VERSION ""

NS_ :

BS_:

BU_: Vector__XXX ECU SenderNode

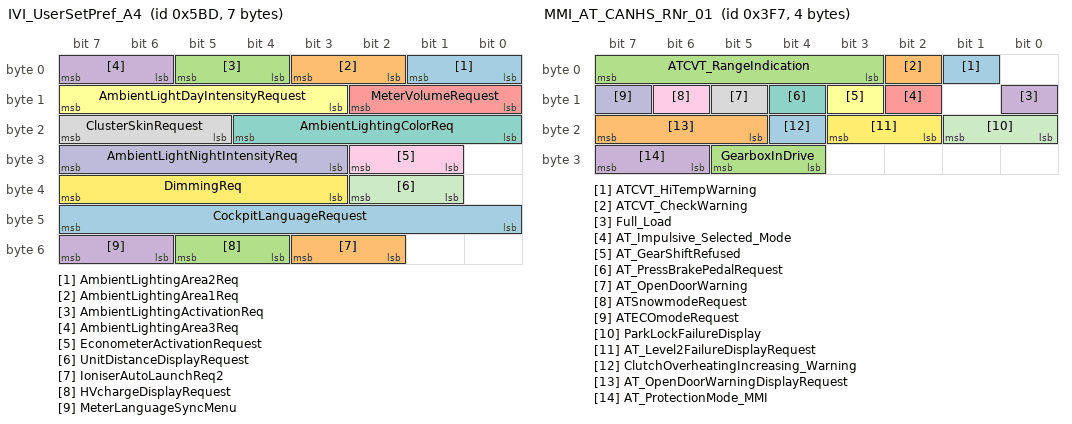
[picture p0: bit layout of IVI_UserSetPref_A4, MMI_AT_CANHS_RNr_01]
BO_ 1469 IVI_UserSetPref_A4: 7 Vector__XXX
 SG_ AmbientLightingArea2Req : 1|2@0+ (1.0,0.0) [0|0] "" Vector__XXX
 SG_ AmbientLightingArea1Req : 3|2@0+ (1.0,0.0) [0|0] "" Vector__XXX
 SG_ AmbientLightingActivationReq : 5|2@0+ (1.0,0.0) [0|0] "" Vector__XXX
 SG_ AmbientLightingArea3Req : 7|2@0+ (1.0,0.0) [0|0] "" Vector__XXX
 SG_ MeterVolumeRequest : 10|3@0+ (1.0,0.0) [0|0] "" Vector__XXX
 SG_ AmbientLightDayIntensityRequest : 15|5@0+ (1.0,0.0) [0|0] "" Vector__XXX
 SG_ AmbientLightingColorReq : 20|5@0+ (1.0,0.0) [0|0] "" Vector__XXX
 SG_ ClusterSkinRequest : 23|3@0+ (1.0,0.0) [0|0] "" Vector__XXX
 SG_ EconometerActivationRequest : 26|2@0+ (1.0,0.0) [0|0] "" Vector__XXX
 SG_ AmbientLightNightIntensityReq : 31|5@0+ (1.0,0.0) [0|0] "" Vector__XXX
 SG_ UnitDistanceDisplayRequest : 34|2@0+ (1.0,0.0) [0|0] "" Vector__XXX
 SG_ DimmingReq : 39|5@0+ (1.0,0.0) [0|0] "" Vector__XXX
 SG_ CockpitLanguageRequest : 47|8@0+ (1.0,0.0) [0|0] "" Vector__XXX
 SG_ IoniserAutoLaunchReq2 : 51|2@0+ (1.0,0.0) [0|0] "" Vector__XXX
 SG_ HVchargeDisplayRequest : 53|2@0+ (1.0,0.0) [0|0] "" Vector__XXX
 SG_ MeterLanguageSyncMenu : 55|2@0+ (1.0,0.0) [0|0] "" Vector__XXX

BO_ 1974 LBC2_to_DTOOL: 8 Vector__XXX
 SG_ LBC2_to_DTOOL : 7|64@0+ (1.0,0.0) [0|0] "" Vector__XXX

BO_ 1199 LBC_CANHS_R_09: 5 Vector__XXX
 SG_ ClosedCircuit_CellMaxVoltage_Threshold : 0|9@0+ (1.0,0.0) [0|0] "" Vector__XXX
 SG_ HVB_TempMinStopCooling_Threshold : 7|7@0+ (1.0,0.0) [0|0] "" Vector__XXX
 SG_ ClosedCircuit_CellMinVoltage_Threshold : 23|9@0+ (1.0,0.0) [0|0] "" Vector__XXX
 SG_ HVB_MaxCapacity : 30|9@0+ (0.1,0.0) [0|0] "kWh" Vector__XXX

BO_ 1979 LBC_to_DTOOL: 8 Vector__XXX
 SG_ LBC_to_DTOOL : 7|64@0+ (1.0,0.0) [0|0] "" Vector__XXX

BO_ 1826 LINSCH_to_DTOOL: 8 Vector__XXX
 SG_ LINSCH_to_DTOOL : 7|64@0+ (1.0,0.0) [0|0] "" Vector__XXX

BO_ 1015 MMI_AT_CANHS_RNr_01: 4 Vector__XXX
 SG_ ATCVT_HiTempWarning : 1|1@0+ (1.0,0.0) [0|0] "" Vector__XXX
 SG_ ATCVT_CheckWarning : 2|1@0+ (1.0,0.0) [0|0] "" Vector__XXX
 SG_ ATCVT_RangeIndication : 7|5@0+ (1.0,0.0) [0|0] "" Vector__XXX
 SG_ Full_Load : 8|1@0+ (1.0,0.0) [0|0] "" Vector__XXX
 SG_ AT_Impulsive_Selected_Mode : 10|1@0+ (1.0,0.0) [0|0] "" Vector__XXX
 SG_ AT_GearShiftRefused : 11|1@0+ (1.0,0.0) [0|0] "" Vector__XXX
 SG_ AT_PressBrakePedalRequest : 12|1@0+ (1.0,0.0) [0|0] "" Vector__XXX
 SG_ AT_OpenDoorWarning : 13|1@0+ (1.0,0.0) [0|0] "" Vector__XXX
 SG_ ATSnowmodeRequest : 14|1@0+ (1.0,0.0) [0|0] "" Vector__XXX
 SG_ ATECOmodeRequest : 15|1@0+ (1.0,0.0) [0|0] "" Vector__XXX
 SG_ ParkLockFailureDisplay : 17|2@0+ (1.0,0.0) [0|0] "" Vector__XXX
 SG_ AT_Level2FailureDisplayRequest : 19|2@0+ (1.0,0.0) [0|0] "" Vector__XXX
 SG_ ClutchOverheatingIncreasing_Warning : 20|1@0+ (1.0,0.0) [0|0] "" Vector__XXX
 SG_ AT_OpenDoorWarningDisplayRequest : 23|3@0+ (1.0,0.0) [0|0] "" Vector__XXX
 SG_ GearboxInDrive : 29|2@0+ (1.0,0.0) [0|0] "" Vector__XXX
 SG_ AT_ProtectionMode_MMI : 31|2@0+ (1.0,0.0) [0|0] "" Vector__XXX

BO_ 1502 MMI_BCM_CANHS_R_01: 8 Vector__XXX
 SG_ HighBeamDisplay : 0|1@0+ (1.0,0.0) [0|0] "" Vector__XXX
 SG_ LowBeamDisplay : 1|1@0+ (1.0,0.0) [0|0] "" Vector__XXX
 SG_ PositionLightsDisplay : 2|1@0+ (1.0,0.0) [0|0] "" Vector__XXX
 SG_ FrontFogLightsDisplay : 3|1@0+ (1.0,0.0) [0|0] "" Vector__XXX
 SG_ RearFogLightStateDisplay : 4|1@0+ (1.0,0.0) [0|0] "" Vector__XXX
 SG_ FlashingIndicatorStatusDisplay : 7|3@0+ (1.0,0.0) [0|0] "" Vector__XXX
 SG_ KeyInfoReemissionRequest : 8|1@0+ (1.0,0.0) [0|0] "" Vector__XXX
 SG_ FrontRightDoorOpenWarning : 10|2@0+ (1.0,0.0) [0|0] "" Vector__XXX
 SG_ FrontLeftDoorOpenWarning : 12|2@0+ (1.0,0.0) [0|0] "" Vector__XXX
 SG_ ALS_Malfunction : 13|1@0+ (1.0,0.0) [0|0] "" Vector__XXX
 SG_ PositionLightsOmissionWarning : 15|2@0+ (1.0,0.0) [0|0] "" Vector__XXX
 SG_ UnlockingSteeringColumnWarning : 16|1@0+ (1.0,0.0) [0|0] "" Vector__XXX
 SG_ SteeringLock_Failure : 18|2@0+ (1.0,0.0) [0|0] "" Vector__XXX
 SG_ BDUSafetyLineFailure : 19|1@0+ (1.0,0.0) [0|0] "" Vector__XXX
 SG_ RearRightDoorOpenWarning : 21|2@0+ (1.0,0.0) [0|0] "" Vector__XXX
 SG_ RearLeftDoorOpenWarning : 23|2@0+ (1.0,0.0) [0|0] "" Vector__XXX
 SG_ StartAutoInformationDisplay : 25|2@0+ (1.0,0.0) [0|0] "" Vector__XXX
 SG_ TripDisplayScrollingRequest : 27|2@0+ (1.0,0.0) [0|0] "" Vector__XXX
 SG_ ChildproofLockMalfunctionDisplay : 29|2@0+ (1.0,0.0) [0|0] "" Vector__XXX
 SG_ BadgeBatteryLow : 30|1@0+ (1.0,0.0) [0|0] "" Vector__XXX
 SG_ AutomaticLockUpActivationState : 31|1@0+ (1.0,0.0) [0|0] "" Vector__XXX
 SG_ DRLstate : 33|2@0+ (1.0,0.0) [0|0] "" Vector__XXX
 SG_ KeylessCardReaderFailureDisplay : 34|1@0+ (1.0,0.0) [0|0] "" Vector__XXX
 SG_ KeylessInfoReemissionRequest : 35|1@0+ (1.0,0.0) [0|0] "" Vector__XXX
 SG_ SmartKeylessInformationDisplay : 39|4@0+ (1.0,0.0) [0|0] "" Vector__XXX
 SG_ BrakeSwitchFaultDisplay : 40|1@0+ (1.0,0.0) [0|0] "" Vector__XXX
 SG_ ClutchSwitchFaultDisplay : 41|1@0+ (1.0,0.0) [0|0] "" Vector__XXX
 SG_ ManualLockDisplayRequest : 42|1@0+ (1.0,0.0) [0|0] "" Vector__XXX
 SG_ SingleDoorOpeningState : 44|2@0+ (1.0,0.0) [0|0] "" Vector__XXX
 SG_ FollowMeHomeDurationDisplay : 47|3@0+ (1.0,0.0) [0|0] "" Vector__XXX
 SG_ KeyInformationDisplay : 50|3@0+ (1.0,0.0) [0|0] "" Vector__XXX
 SG_ AutomaticLockUpInhibitionWarning : 51|1@0+ (1.0,0.0) [0|0] "" Vector__XXX
 SG_ VarPowSteeringFailureDisplay : 52|1@0+ (1.0,0.0) [0|0] "" Vector__XXX
 SG_ FlashingIndicatorFailureDisplay : 53|1@0+ (1.0,0.0) [0|0] "" Vector__XXX
 SG_ StopLampFailureDisplay_BCM : 54|1@0+ (1.0,0.0) [0|0] "" Vector__XXX
 SG_ MexSwitchState : 55|1@0+ (1.0,0.0) [0|0] "" Vector__XXX
 SG_ EcoModeStatusDisplay : 57|2@0+ (1.0,0.0) [0|0] "" Vector__XXX
 SG_ GlasshatchOpenWarning : 59|2@0+ (1.0,0.0) [0|0] "" Vector__XXX
 SG_ BootOpenWarning : 61|2@0+ (1.0,0.0) [0|0] "" Vector__XXX
 SG_ RearWiperStatus : 63|2@0+ (1.0,0.0) [0|0] "" Vector__XXX

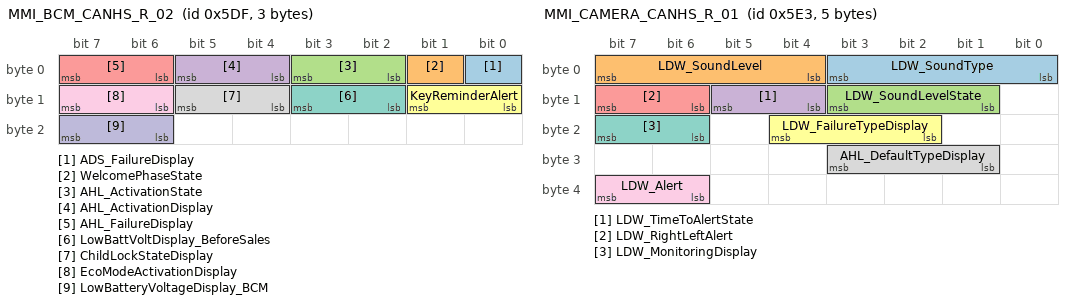
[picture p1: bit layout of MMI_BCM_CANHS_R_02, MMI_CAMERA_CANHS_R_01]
BO_ 1503 MMI_BCM_CANHS_R_02: 3 Vector__XXX
 SG_ ADS_FailureDisplay : 0|1@0+ (1.0,0.0) [0|0] "" Vector__XXX
 SG_ WelcomePhaseState : 1|1@0+ (1.0,0.0) [0|0] "" Vector__XXX
 SG_ AHL_ActivationState : 3|2@0+ (1.0,0.0) [0|0] "" Vector__XXX
 SG_ AHL_ActivationDisplay : 5|2@0+ (1.0,0.0) [0|0] "" Vector__XXX
 SG_ AHL_FailureDisplay : 7|2@0+ (1.0,0.0) [0|0] "" Vector__XXX
 SG_ KeyReminderAlert : 9|2@0+ (1.0,0.0) [0|0] "" Vector__XXX
 SG_ LowBattVoltDisplay_BeforeSales : 11|2@0+ (1.0,0.0) [0|0] "" Vector__XXX
 SG_ ChildLockStateDisplay : 13|2@0+ (1.0,0.0) [0|0] "" Vector__XXX
 SG_ EcoModeActivationDisplay : 15|2@0+ (1.0,0.0) [0|0] "" Vector__XXX
 SG_ LowBatteryVoltageDisplay_BCM : 23|2@0+ (1.0,0.0) [0|0] "" Vector__XXX

BO_ 1638 MMI_BRAKE_CANHS_RNr_01: 4 Vector__XXX
 SG_ EmergencyBrakingFailure : 0|1@0+ (1.0,0.0) [0|0] "" Vector__XXX
 SG_ EBVInDefaultDisplayRequest : 1|1@0+ (1.0,0.0) [0|0] "" Vector__XXX
 SG_ ESPDeactivatedByDriverForDisplay : 2|1@0+ (1.0,0.0) [0|0] "" Vector__XXX
 SG_ ABSInDefaultDisplayRequest : 3|1@0+ (1.0,0.0) [0|0] "" Vector__XXX
 SG_ ASRActivationStateForDisplay : 4|1@0+ (1.0,0.0) [0|0] "" Vector__XXX
 SG_ ESPActivationStateForDisplay : 5|1@0+ (1.0,0.0) [0|0] "" Vector__XXX
 SG_ ESPInDefaultDisplayRequest : 6|1@0+ (1.0,0.0) [0|0] "" Vector__XXX
 SG_ ESPInRegulationDisplayRequest : 7|1@0+ (1.0,0.0) [0|0] "" Vector__XXX
 SG_ ABSorESPToBeCalibrated : 8|1@0+ (1.0,0.0) [0|0] "" Vector__XXX
 SG_ ABSorESPInCalibratingDiag : 9|1@0+ (1.0,0.0) [0|0] "" Vector__XXX
 SG_ FHSA_MalfunctionDisplayRequest : 10|1@0+ (1.0,0.0) [0|0] "" Vector__XXX
 SG_ FHSA_DriverActionRequest : 11|1@0+ (1.0,0.0) [0|0] "" Vector__XXX
 SG_ FHSA_HoldStatusDisplayRequest : 12|1@0+ (1.0,0.0) [0|0] "" Vector__XXX
 SG_ FHSA_DeactivationDisplayRequest : 14|2@0+ (1.0,0.0) [0|0] "" Vector__XXX
 SG_ ABS_ESPLampsAutoCheck : 15|1@0+ (1.0,0.0) [0|0] "" Vector__XXX
 SG_ HSAFailureDisplayRequest : 16|1@0+ (1.0,0.0) [0|0] "" Vector__XXX
 SG_ ACCInactiveRegulationDisplay : 18|2@0+ (1.0,0.0) [0|0] "" Vector__XXX
 SG_ RST_EspAsrSportMode : 21|3@0+ (1.0,0.0) [0|0] "" Vector__XXX
 SG_ VSUStateDisplayRequest : 23|2@0+ (1.0,0.0) [0|0] "" Vector__XXX
 SG_ TPW_AckResetDriver : 25|2@0+ (1.0,0.0) [0|0] "" Vector__XXX
 SG_ TPW_Status : 27|2@0+ (1.0,0.0) [0|0] "" Vector__XXX
 SG_ ExtendedGripModeDisplayRequest : 30|3@0+ (1.0,0.0) [0|0] "" Vector__XXX
 SG_ HSA_HoldStatusDisplayRequest : 31|1@0+ (1.0,0.0) [0|0] "" Vector__XXX

BO_ 1507 MMI_CAMERA_CANHS_R_01: 5 Vector__XXX
 SG_ LDW_SoundType : 3|4@0+ (1.0,0.0) [0|0] "" Vector__XXX
 SG_ LDW_SoundLevel : 7|4@0+ (1.0,0.0) [0|0] "" Vector__XXX
 SG_ LDW_SoundLevelState : 11|3@0+ (1.0,0.0) [0|0] "" Vector__XXX
 SG_ LDW_TimeToAlertState : 13|2@0+ (1.0,0.0) [0|0] "" Vector__XXX
 SG_ LDW_RightLeftAlert : 15|2@0+ (1.0,0.0) [0|0] "" Vector__XXX
 SG_ LDW_FailureTypeDisplay : 20|3@0+ (1.0,0.0) [0|0] "" Vector__XXX
 SG_ LDW_MonitoringDisplay : 23|2@0+ (1.0,0.0) [0|0] "" Vector__XXX
 SG_ AHL_DefaultTypeDisplay : 27|3@0+ (1.0,0.0) [0|0] "" Vector__XXX
 SG_ LDW_Alert : 39|2@0+ (1.0,0.0) [0|0] "" Vector__XXX

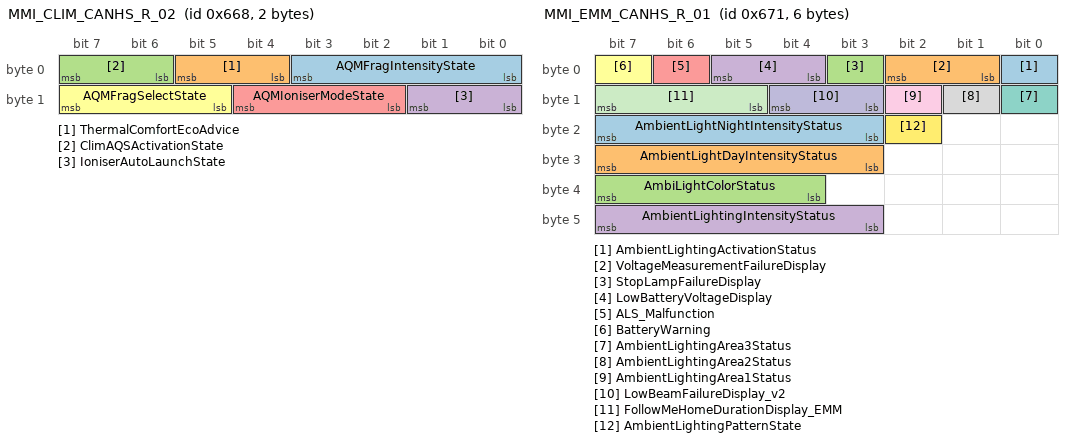
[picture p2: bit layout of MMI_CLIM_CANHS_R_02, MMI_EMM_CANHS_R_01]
BO_ 1640 MMI_CLIM_CANHS_R_02: 2 Vector__XXX
 SG_ AQMFragIntensityState : 3|4@0+ (1.0,0.0) [0|0] "" Vector__XXX
 SG_ ThermalComfortEcoAdvice : 5|2@0+ (1.0,0.0) [0|0] "" Vector__XXX
 SG_ ClimAQSActivationState : 7|2@0+ (1.0,0.0) [0|0] "" Vector__XXX
 SG_ IoniserAutoLaunchState : 9|2@0+ (1.0,0.0) [0|0] "" Vector__XXX
 SG_ AQMIoniserModeState : 12|3@0+ (1.0,0.0) [0|0] "" Vector__XXX
 SG_ AQMFragSelectState : 15|3@0+ (1.0,0.0) [0|0] "" Vector__XXX

BO_ 1689 MMI_CLIM_CANHS_R_03: 8 Vector__XXX
 SG_ ClimModeTypeDisplay : 3|3@0+ (1.0,0.0) [0|0] "" Vector__XXX
 SG_ ClimRearDefrostDisplay : 5|2@0+ (1.0,0.0) [0|0] "" Vector__XXX
 SG_ ClimOFFButtonDisplay : 7|2@0+ (1.0,0.0) [0|0] "" Vector__XXX
 SG_ ClimTempDisplay : 15|8@0+ (1.0,0.0) [0|0] "" Vector__XXX
 SG_ ClimECOModeStatusDisplay : 17|2@0+ (1.0,0.0) [0|0] "" Vector__XXX
 SG_ ClimForcedRecyDisplay : 19|2@0+ (1.0,0.0) [0|0] "" Vector__XXX
 SG_ ClimFlowDistrDisplay : 23|4@0+ (1.0,0.0) [0|0] "" Vector__XXX
 SG_ ClimLastFuncModifiedByCustomer : 27|4@0+ (1.0,0.0) [0|0] "" Vector__XXX
 SG_ ClimBlowerLevelDisplay : 31|4@0+ (1.0,0.0) [0|0] "" Vector__XXX
 SG_ ClimAQSIndicator : 37|6@0+ (2.0,0.0) [0|0] "%" Vector__XXX
 SG_ ClimMMIActivationRequest : 39|2@0+ (1.0,0.0) [0|0] "" Vector__XXX
 SG_ ClimAQMIoniserTimerDisplay : 41|6@0+ (1.0,0.0) [0|0] "" Vector__XXX
 SG_ ClimAQMIoniserMaxTimerDisplay : 47|6@0+ (1.0,0.0) [0|0] "" Vector__XXX
 SG_ ClimACOffDisplay : 49|2@0+ (1.0,0.0) [0|0] "" Vector__XXX
 SG_ ClimAutoDisplay : 51|2@0+ (1.0,0.0) [0|0] "" Vector__XXX
 SG_ ClimEcoLowSocDisplay : 56|1@0+ (1.0,0.0) [0|0] "" Vector__XXX
 SG_ ClimOFFPromptingDisplay : 57|1@0+ (1.0,0.0) [0|0] "" Vector__XXX
 SG_ EnergyFlowForThermalComfortDisplay : 59|2@0+ (1.0,0.0) [0|0] "" Vector__XXX
 SG_ ClimDisplayMenuPC : 61|2@0+ (1.0,0.0) [0|0] "" Vector__XXX
 SG_ ClimClearnessDisplay : 63|2@0+ (1.0,0.0) [0|0] "" Vector__XXX

BO_ 1642 MMI_ECM_CANHS_RNr_01: 8 Vector__XXX
 SG_ CruiseControlStatusDisplay : 2|3@0+ (1.0,0.0) [0|0] "" Vector__XXX
 SG_ MILLamp : 6|4@0+ (1.0,0.0) [0|0] "" Vector__XXX
 SG_ DieselPreHeating : 7|1@0+ (1.0,0.0) [0|0] "" Vector__XXX
 SG_ RequestedSpeedDisplayRequest : 15|8@0+ (1.0,0.0) [0|0] "" Vector__XXX
 SG_ FuelConsumptionType : 16|1@0+ (1.0,0.0) [0|0] "" Vector__XXX
 SG_ ParticulateFilterFailureDisplay : 17|1@0+ (1.0,0.0) [0|0] "" Vector__XXX
 SG_ ParticulateFilterState : 18|1@0+ (1.0,0.0) [0|0] "" Vector__XXX
 SG_ DieselFilterWaterDetection : 19|1@0+ (1.0,0.0) [0|0] "" Vector__XXX
 SG_ WarningWaterTemp : 20|1@0+ (1.0,0.0) [0|0] "" Vector__XXX
 SG_ EngineControlFailureLevel2 : 21|1@0+ (1.0,0.0) [0|0] "" Vector__XXX
 SG_ EngineControlFailureLevel1 : 22|1@0+ (1.0,0.0) [0|0] "" Vector__XXX
 SG_ OverspeedIndicationDisplayReq : 23|1@0+ (1.0,0.0) [0|0] "" Vector__XXX
 SG_ FuelConsumption : 31|8@0+ (80.0,0.0) [0|0] "mm3" Vector__XXX
 SG_ NominalFuelConsumption : 39|8@0+ (80.0,0.0) [0|0] "mm3" Vector__XXX
 SG_ DMSActivationRefusedDisplay : 40|2@0+ (1.0,0.0) [0|0] "" Vector__XXX
 SG_ DMSFailureDisplay : 41|1@0+ (1.0,0.0) [0|0] "" Vector__XXX
 SG_ DMSActivationStateDisplay : 42|1@0+ (1.0,0.0) [0|0] "" Vector__XXX
 SG_ RST_GearShift : 43|1@0+ (1.0,0.0) [0|0] "" Vector__XXX
 SG_ LPGFlowSwitchedOFFWarning : 44|1@0+ (1.0,0.0) [0|0] "" Vector__XXX
 SG_ CCSpeedReachedDisplayReq : 45|1@0+ (1.0,0.0) [0|0] "" Vector__XXX
 SG_ FreeShift : 47|2@0+ (1.0,0.0) [0|0] "" Vector__XXX
 SG_ EnginePowerDisplay : 52|5@0+ (1.0,0.0) [0|0] "" Vector__XXX
 SG_ AdditionalTankFuelLowLevel : 53|1@0+ (1.0,0.0) [0|0] "" Vector__XXX
 SG_ OverSpeedAlert_SL : 54|1@0+ (1.0,0.0) [0|0] "" Vector__XXX
 SG_ RST_VehicleMode_MMI : 59|3@0+ (1.0,0.0) [0|0] "" Vector__XXX

BO_ 1608 MMI_ECM_CANHS_R_02: 8 Vector__XXX
 SG_ SCR_DistanceAutonomyDisplay : 1|10@0+ (1.0,0.0) [0|0] "" Vector__XXX
 SG_ SCR_UreaLevelDisplay : 5|4@0+ (1.0,0.0) [0|0] "" Vector__XXX
 SG_ SCR_WarningDISDisplay : 7|2@0+ (1.0,0.0) [0|0] "" Vector__XXX
 SG_ SailingIdleDisplay : 16|2@0+ (1.0,0.0) [0|0] "" Vector__XXX
 SG_ SailingActivationIdleStatus : 17|1@0+ (1.0,0.0) [0|0] "" Vector__XXX
 SG_ SCR_WarningPostDISDisplay : 19|2@0+ (1.0,0.0) [0|0] "" Vector__XXX
 SG_ SCR_QualityWarningBeforeDISDisplay : 21|2@0+ (1.0,0.0) [0|0] "" Vector__XXX
 SG_ SCR_WarningBeforeDISDisplay : 23|2@0+ (1.0,0.0) [0|0] "" Vector__XXX
 SG_ AccelerationIndicator : 30|7@0+ (1.0,0.0) [0|0] "%" Vector__XXX
 SG_ FluentDrivingIndicator : 39|7@0+ (1.0,0.0) [0|0] "%" Vector__XXX
 SG_ GSI_Respect : 46|7@0+ (1.0,0.0) [0|0] "%" Vector__XXX
 SG_ LPGModeDisplayRequest : 48|1@0+ (1.0,0.0) [0|0] "" Vector__XXX
 SG_ AdvisorEconometer : 55|7@0+ (1.0,0.0) [0|0] "%" Vector__XXX
 SG_ SCR_DISWarningDisplayReactivation : 56|1@0+ (1.0,0.0) [0|0] "" Vector__XXX
 SG_ FlexFuelPreHeatingDisplay : 58|2@0+ (1.0,0.0) [0|0] "" Vector__XXX
 SG_ SCR_DISFinalWarningDisplay : 60|2@0+ (1.0,0.0) [0|0] "" Vector__XXX
 SG_ CapFuelTankStatusDisplay : 62|2@0+ (1.0,0.0) [0|0] "" Vector__XXX
 SG_ LPG_NGSystemMalfunction : 63|1@0+ (1.0,0.0) [0|0] "" Vector__XXX

BO_ 1050 MMI_ECM_CANHS_R_03: 8 Vector__XXX
 SG_ StartAutoInformationDisplay_ECM : 1|2@0+ (1.0,0.0) [0|0] "" Vector__XXX
 SG_ StopStartSwitchMMI : 2|1@0+ (1.0,0.0) [0|0] "" Vector__XXX
 SG_ StopStartExitReminderDisplay_ECM : 4|2@0+ (1.0,0.0) [0|0] "" Vector__XXX
 SG_ StopAutoUnavailableDisplayRequest_ECM : 5|1@0+ (1.0,0.0) [0|0] "" Vector__XXX
 SG_ StopStartStateDisplayRequest_ECM : 7|2@0+ (1.0,0.0) [0|0] "" Vector__XXX
 SG_ BattWarnReq_Level_Lo_ECM : 8|1@0+ (1.0,0.0) [0|0] "" Vector__XXX
 SG_ BattWarnReq_Level_Hi_ECM : 9|1@0+ (1.0,0.0) [0|0] "" Vector__XXX
 SG_ ECM_OilPressureSwitchFaultDisplay : 10|1@0+ (1.0,0.0) [0|0] "" Vector__XXX
 SG_ DeclutchPromptingDisplayRequest_ECM : 12|2@0+ (1.0,0.0) [0|0] "" Vector__XXX
 SG_ StopStartManualCrankingDisplay : 15|3@0+ (1.0,0.0) [0|0] "" Vector__XXX
 SG_ ManualPartFilterRegeStatus : 19|2@0+ (1.0,0.0) [0|0] "" Vector__XXX
 SG_ GasLowLevelAlertDisplayRequest : 20|1@0+ (1.0,0.0) [0|0] "" Vector__XXX
 SG_ GasInstantCarburationMod : 21|1@0+ (1.0,0.0) [0|0] "" Vector__XXX
 SG_ StopAutoStateDisplayRequest_ECM : 22|1@0+ (1.0,0.0) [0|0] "" Vector__XXX
 SG_ OilPressureWarning_ECM : 23|1@0+ (1.0,0.0) [0|0] "" Vector__XXX
 SG_ SCR_UreaLevelDisplay_V2 : 31|8@0+ (1.0,0.0) [0|0] "" Vector__XXX
 SG_ CNGFuelConsumption : 39|8@0+ (1e-05,0.0) [0|0] "kg" Vector__XXX
 SG_ LPGLevelForDisplay : 47|8@0+ (0.25,0.0) [0|0] "L" Vector__XXX
 SG_ LPGFuelConsumption : 55|8@0+ (2e-05,0.0) [0|0] "L" Vector__XXX
 SG_ CNGLevelForDisplay : 63|8@0+ (0.2,0.0) [0|0] "kg" Vector__XXX

BO_ 1649 MMI_EMM_CANHS_R_01: 6 Vector__XXX
 SG_ AmbientLightingActivationStatus : 0|1@0+ (1.0,0.0) [0|0] "" Vector__XXX
 SG_ VoltageMeasurementFailureDisplay : 2|2@0+ (1.0,0.0) [0|0] "" Vector__XXX
 SG_ StopLampFailureDisplay : 3|1@0+ (1.0,0.0) [0|0] "" Vector__XXX
 SG_ LowBatteryVoltageDisplay : 5|2@0+ (1.0,0.0) [0|0] "" Vector__XXX
 SG_ ALS_Malfunction : 6|1@0+ (1.0,0.0) [0|0] "" Vector__XXX
 SG_ BatteryWarning : 7|1@0+ (1.0,0.0) [0|0] "" Vector__XXX
 SG_ AmbientLightingArea3Status : 8|1@0+ (1.0,0.0) [0|0] "" Vector__XXX
 SG_ AmbientLightingArea2Status : 9|1@0+ (1.0,0.0) [0|0] "" Vector__XXX
 SG_ AmbientLightingArea1Status : 10|1@0+ (1.0,0.0) [0|0] "" Vector__XXX
 SG_ LowBeamFailureDisplay_v2 : 12|2@0+ (1.0,0.0) [0|0] "" Vector__XXX
 SG_ FollowMeHomeDurationDisplay_EMM : 15|3@0+ (1.0,0.0) [0|0] "" Vector__XXX
 SG_ AmbientLightingPatternState : 18|1@0+ (1.0,0.0) [0|0] "" Vector__XXX
 SG_ AmbientLightNightIntensityStatus : 23|5@0+ (1.0,0.0) [0|0] "" Vector__XXX
 SG_ AmbientLightDayIntensityStatus : 31|5@0+ (1.0,0.0) [0|0] "" Vector__XXX
 SG_ AmbiLightColorStatus : 39|4@0+ (1.0,0.0) [0|0] "" Vector__XXX
 SG_ AmbientLightingIntensityStatus : 47|5@0+ (1.0,0.0) [0|0] "" Vector__XXX

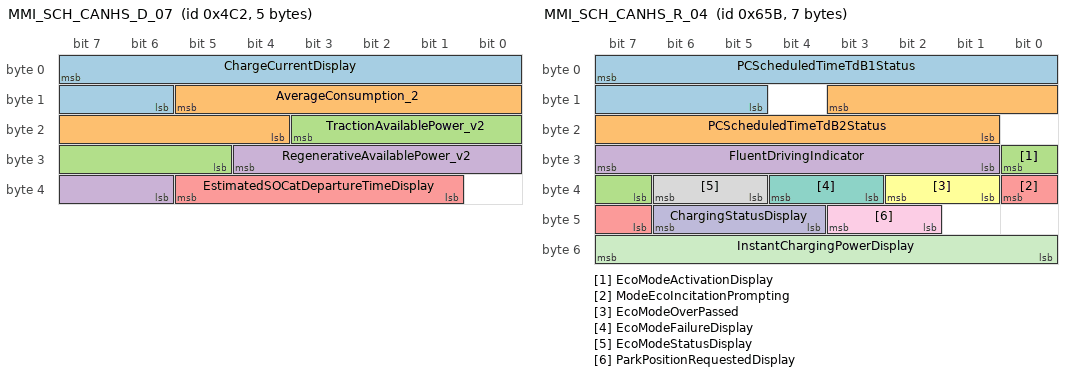
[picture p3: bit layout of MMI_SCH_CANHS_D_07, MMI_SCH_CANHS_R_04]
BO_ 1218 MMI_SCH_CANHS_D_07: 5 Vector__XXX
 SG_ ChargeCurrentDisplay : 7|10@0+ (0.1,0.0) [0|0] "A" Vector__XXX
 SG_ AverageConsumption_2 : 13|10@0+ (0.1,0.0) [0|0] "kWh/100km" Vector__XXX
 SG_ TractionAvailablePower_v2 : 19|7@0+ (1.0,0.0) [0|0] "KW" Vector__XXX
 SG_ RegenerativeAvailablePower_v2 : 28|7@0+ (1.0,0.0) [0|0] "KW" Vector__XXX
 SG_ EstimatedSOCatDepartureTimeDisplay : 37|5@0+ (5.0,0.0) [0|0] "%" Vector__XXX

BO_ 1618 MMI_SCH_CANHS_R_01: 8 Vector__XXX
 SG_ ElectricalConsumption : 7|8@0+ (1.0,0.0) [0|0] "" Vector__XXX
 SG_ InstantConsumption : 11|12@0+ (1.0,0.0) [0|0] "" Vector__XXX
 SG_ Battery14VLowDisplayRequest : 13|2@0+ (1.0,0.0) [0|0] "" Vector__XXX
 SG_ ElectricalEngineState : 14|1@0+ (1.0,0.0) [0|0] "" Vector__XXX
 SG_ CrankingRequest : 15|1@0+ (1.0,0.0) [0|0] "" Vector__XXX
 SG_ ETAlertIsolationLevel1 : 25|2@0+ (1.0,0.0) [0|0] "" Vector__XXX
 SG_ ETAlertETSDefault : 27|2@0+ (1.0,0.0) [0|0] "" Vector__XXX
 SG_ ETAlertRepairETSDefault : 29|2@0+ (1.0,0.0) [0|0] "" Vector__XXX
 SG_ Battery14VWarningDisplayRequest : 31|2@0+ (1.0,0.0) [0|0] "" Vector__XXX
 SG_ TotalConsumption : 37|14@0+ (1.0,0.0) [0|0] "" Vector__XXX
 SG_ ETAlertIsolationLevel2 : 39|2@0+ (1.0,0.0) [0|0] "" Vector__XXX
 SG_ ETAlertDCDCDefault : 49|2@0+ (1.0,0.0) [0|0] "" Vector__XXX
 SG_ ETAlertPerfLimitation2 : 51|2@0+ (1.0,0.0) [0|0] "" Vector__XXX
 SG_ ETAlertPerfLimitation1 : 53|2@0+ (1.0,0.0) [0|0] "" Vector__XXX
 SG_ ETAlertMotorDefault : 55|2@0+ (1.0,0.0) [0|0] "" Vector__XXX
 SG_ SCH_StopLampRequest : 57|2@0+ (1.0,0.0) [0|0] "" Vector__XXX
 SG_ SCH_WarningRequest : 59|2@0+ (1.0,0.0) [0|0] "" Vector__XXX
 SG_ ETAlertPerfLimitation3 : 61|2@0+ (1.0,0.0) [0|0] "" Vector__XXX
 SG_ EMOverSpeed : 63|2@0+ (1.0,0.0) [0|0] "" Vector__XXX

BO_ 1620 MMI_SCH_CANHS_R_02: 8 Vector__XXX
 SG_ UnballastStateDisplay : 0|1@0+ (1.0,0.0) [0|0] "" Vector__XXX
 SG_ SnowModeRequest : 1|1@0+ (1.0,0.0) [0|0] "" Vector__XXX
 SG_ PedalPressRequested : 2|1@0+ (1.0,0.0) [0|0] "" Vector__XXX
 SG_ HVBatteryUnballastAlert : 3|1@0+ (1.0,0.0) [0|0] "" Vector__XXX
 SG_ DriverWalkAwayEngineON : 4|1@0+ (1.0,0.0) [0|0] "" Vector__XXX
 SG_ ChargingPlugConnected : 5|1@0+ (1.0,0.0) [0|0] "" Vector__XXX
 SG_ BoilerStateDisplay : 6|1@0+ (1.0,0.0) [0|0] "" Vector__XXX
 SG_ BoilerLevelStateDisplay : 7|1@0+ (1.0,0.0) [0|0] "" Vector__XXX
 SG_ HVBatteryFailureDisplay : 15|2@0+ (1.0,0.0) [0|0] "" Vector__XXX
 SG_ DriverWalkAwayBoilerON : 17|1@0+ (1.0,0.0) [0|0] "" Vector__XXX
 SG_ SelectedGear : 19|2@0+ (1.0,0.0) [0|0] "" Vector__XXX
 SG_ PreHeatingState : 21|2@0+ (1.0,0.0) [0|0] "" Vector__XXX
 SG_ ElectricalChargingType : 23|2@0+ (1.0,0.0) [0|0] "" Vector__XXX
 SG_ HVBatteryEnergyLevel : 30|7@0+ (1.0,0.0) [0|0] "%" Vector__XXX
 SG_ DriverWalkAwayOnParking_Request : 31|1@0+ (1.0,0.0) [0|0] "" Vector__XXX
 SG_ SlowChargeRemainingTime : 39|10@0+ (1.0,0.0) [0|0] "min" Vector__XXX
 SG_ VehicleAutonomy : 45|10@0+ (1.0,0.0) [0|0] "km" Vector__XXX
 SG_ AverageConsumption : 51|10@0+ (0.1,0.0) [0|0] "kWh/100km" Vector__XXX
 SG_ HVBatteryLow : 56|1@0+ (1.0,0.0) [0|0] "" Vector__XXX

BO_ 1616 MMI_SCH_CANHS_R_03: 8 Vector__XXX
 SG_ EnergyFlowForTractionDisplay : 1|2@0+ (1.0,0.0) [0|0] "" Vector__XXX
 SG_ EnergyFlowForThermalComfortDisplay : 3|2@0+ (1.0,0.0) [0|0] "" Vector__XXX
 SG_ EnergyFlowForHardBrakingDisplay : 5|2@0+ (1.0,0.0) [0|0] "" Vector__XXX
 SG_ EnergyFlowForEnergyRecoveringDisplay : 7|2@0+ (1.0,0.0) [0|0] "" Vector__XXX
 SG_ QuickDropUnlockedDisplay : 9|2@0+ (1.0,0.0) [0|0] "" Vector__XXX
 SG_ QuickDropLockFailureDisplay : 11|2@0+ (1.0,0.0) [0|0] "" Vector__XXX
 SG_ QuickDropIterationExceededDisplay : 13|2@0+ (1.0,0.0) [0|0] "" Vector__XXX
 SG_ ShortRangeDisplay : 15|2@0+ (1.0,0.0) [0|0] "" Vector__XXX
 SG_ AdvisorEconometer : 23|7@0+ (1.0,0.0) [0|0] "%" Vector__XXX
 SG_ CrankingPluggedDisplay : 25|2@0+ (1.0,0.0) [0|0] "" Vector__XXX
 SG_ EBAAlertLevel2 : 27|2@0+ (1.0,0.0) [0|0] "" Vector__XXX
 SG_ EBAAlertLevel1 : 29|2@0+ (1.0,0.0) [0|0] "" Vector__XXX
 SG_ JBDefaultLevel2 : 35|2@0+ (1.0,0.0) [0|0] "" Vector__XXX
 SG_ JBDefaultLevel1 : 37|2@0+ (1.0,0.0) [0|0] "" Vector__XXX
 SG_ GearboxChangeOnCrankingRequest : 39|2@0+ (1.0,0.0) [0|0] "" Vector__XXX
 SG_ ChargeRemainingTimeDisplay : 41|9@0+ (5.0,0.0) [0|0] "min" Vector__XXX
 SG_ HVConnectionStatusDisplay : 42|1@0+ (1.0,0.0) [0|0] "" Vector__XXX
 SG_ PreHeatingStateDisplay : 45|3@0+ (1.0,0.0) [0|0] "" Vector__XXX
 SG_ ClimProgrammedPCDisplay : 47|2@0+ (1.0,0.0) [0|0] "" Vector__XXX
 SG_ RadarRecuperationStatusDisplay : 57|2@0+ (1.0,0.0) [0|0] "" Vector__XXX
 SG_ EngineDryingDisplayRequest : 63|2@0+ (1.0,0.0) [0|0] "" Vector__XXX

BO_ 1627 MMI_SCH_CANHS_R_04: 7 Vector__XXX
 SG_ PCScheduledTimeTdB1Status : 7|11@0+ (1.0,0.0) [0|0] "min" Vector__XXX
 SG_ PCScheduledTimeTdB2Status : 11|11@0+ (1.0,0.0) [0|0] "min" Vector__XXX
 SG_ EcoModeActivationDisplay : 24|2@0+ (1.0,0.0) [0|0] "" Vector__XXX
 SG_ FluentDrivingIndicator : 31|7@0+ (1.0,0.0) [0|0] "%" Vector__XXX
 SG_ ModeEcoIncitationPrompting : 32|2@0+ (1.0,0.0) [0|0] "" Vector__XXX
 SG_ EcoModeOverPassed : 34|2@0+ (1.0,0.0) [0|0] "" Vector__XXX
 SG_ EcoModeFailureDisplay : 36|2@0+ (1.0,0.0) [0|0] "" Vector__XXX
 SG_ EcoModeStatusDisplay : 38|2@0+ (1.0,0.0) [0|0] "" Vector__XXX
 SG_ ParkPositionRequestedDisplay : 43|2@0+ (1.0,0.0) [0|0] "" Vector__XXX
 SG_ ChargingStatusDisplay : 46|3@0+ (1.0,0.0) [0|0] "" Vector__XXX
 SG_ InstantChargingPowerDisplay : 55|8@0+ (0.3,0.0) [0|0] "kW" Vector__XXX

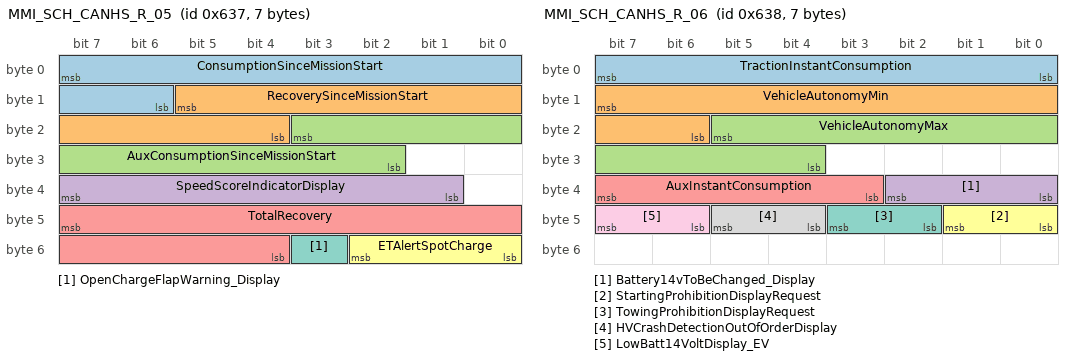
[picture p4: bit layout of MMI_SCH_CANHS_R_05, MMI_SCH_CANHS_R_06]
BO_ 1591 MMI_SCH_CANHS_R_05: 7 Vector__XXX
 SG_ ConsumptionSinceMissionStart : 7|10@0+ (0.1,0.0) [0|0] "kWh" Vector__XXX
 SG_ RecoverySinceMissionStart : 13|10@0+ (0.1,0.0) [0|0] "kWh" Vector__XXX
 SG_ AuxConsumptionSinceMissionStart : 19|10@0+ (0.1,0.0) [0|0] "kWh" Vector__XXX
 SG_ SpeedScoreIndicatorDisplay : 39|7@0+ (1.0,0.0) [0|0] "%" Vector__XXX
 SG_ TotalRecovery : 47|12@0+ (1.0,0.0) [0|0] "kWh" Vector__XXX
 SG_ ETAlertSpotCharge : 50|3@0+ (1.0,0.0) [0|0] "" Vector__XXX
 SG_ OpenChargeFlapWarning_Display : 51|1@0+ (1.0,0.0) [0|0] "" Vector__XXX

BO_ 1592 MMI_SCH_CANHS_R_06: 7 Vector__XXX
 SG_ TractionInstantConsumption : 7|8@0- (1.0,-80.0) [0|0] "kW" Vector__XXX
 SG_ VehicleAutonomyMin : 15|10@0+ (1.0,0.0) [0|0] "km" Vector__XXX
 SG_ VehicleAutonomyMax : 21|10@0+ (1.0,0.0) [0|0] "km" Vector__XXX
 SG_ Battery14vToBeChanged_Display : 34|3@0+ (1.0,0.0) [0|0] "" Vector__XXX
 SG_ AuxInstantConsumption : 39|5@0+ (1.0,0.0) [0|0] "kW" Vector__XXX
 SG_ StartingProhibitionDisplayRequest : 41|2@0+ (1.0,0.0) [0|0] "" Vector__XXX
 SG_ TowingProhibitionDisplayRequest : 43|2@0+ (1.0,0.0) [0|0] "" Vector__XXX
 SG_ HVCrashDetectionOutOfOrderDisplay : 45|2@0+ (1.0,0.0) [0|0] "" Vector__XXX
 SG_ LowBatt14VoltDisplay_EV : 47|2@0+ (1.0,0.0) [0|0] "" Vector__XXX

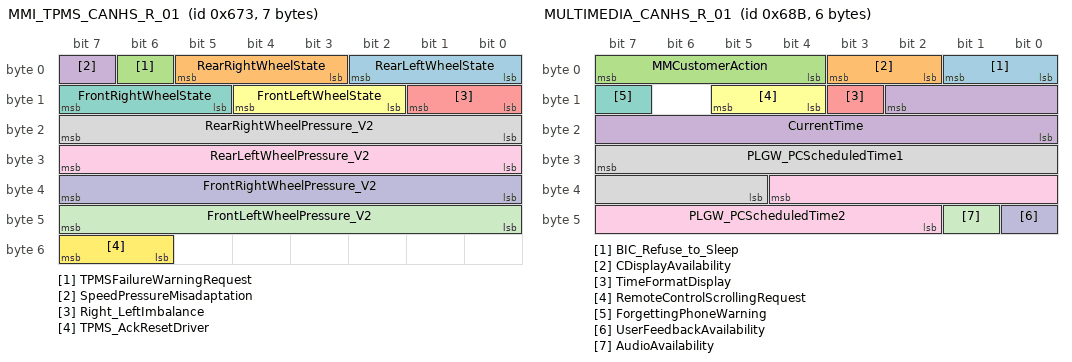
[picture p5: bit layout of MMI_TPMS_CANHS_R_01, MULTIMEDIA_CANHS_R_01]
BO_ 1651 MMI_TPMS_CANHS_R_01: 7 Vector__XXX
 SG_ RearLeftWheelState : 2|3@0+ (1.0,0.0) [0|0] "" Vector__XXX
 SG_ RearRightWheelState : 5|3@0+ (1.0,0.0) [0|0] "" Vector__XXX
 SG_ TPMSFailureWarningRequest : 6|1@0+ (1.0,0.0) [0|0] "" Vector__XXX
 SG_ SpeedPressureMisadaptation : 7|1@0+ (1.0,0.0) [0|0] "" Vector__XXX
 SG_ Right_LeftImbalance : 9|2@0+ (1.0,0.0) [0|0] "" Vector__XXX
 SG_ FrontLeftWheelState : 12|3@0+ (1.0,0.0) [0|0] "" Vector__XXX
 SG_ FrontRightWheelState : 15|3@0+ (1.0,0.0) [0|0] "" Vector__XXX
 SG_ RearRightWheelPressure_V2 : 23|8@0+ (30.0,0.0) [0|0] "mbar" Vector__XXX
 SG_ RearLeftWheelPressure_V2 : 31|8@0+ (30.0,0.0) [0|0] "mbar" Vector__XXX
 SG_ FrontRightWheelPressure_V2 : 39|8@0+ (30.0,0.0) [0|0] "mbar" Vector__XXX
 SG_ FrontLeftWheelPressure_V2 : 47|8@0+ (30.0,0.0) [0|0] "mbar" Vector__XXX
 SG_ TPMS_AckResetDriver : 55|2@0+ (1.0,0.0) [0|0] "" Vector__XXX

BO_ 1675 MULTIMEDIA_CANHS_R_01: 6 Vector__XXX
 SG_ BIC_Refuse_to_Sleep : 1|2@0+ (1.0,0.0) [0|0] "" Vector__XXX
 SG_ CDisplayAvailability : 3|2@0+ (1.0,0.0) [0|0] "" Vector__XXX
 SG_ MMCustomerAction : 7|4@0+ (1.0,0.0) [0|0] "" Vector__XXX
 SG_ CurrentTime : 10|11@0+ (1.0,0.0) [0|0] "min" Vector__XXX
 SG_ TimeFormatDisplay : 11|1@0+ (1.0,0.0) [0|0] "" Vector__XXX
 SG_ RemoteControlScrollingRequest : 13|2@0+ (1.0,0.0) [0|0] "" Vector__XXX
 SG_ ForgettingPhoneWarning : 15|1@0+ (1.0,0.0) [0|0] "" Vector__XXX
 SG_ PLGW_PCScheduledTime1 : 31|11@0+ (1.0,0.0) [0|0] "" Vector__XXX
 SG_ PLGW_PCScheduledTime2 : 36|11@0+ (1.0,0.0) [0|0] "" Vector__XXX
 SG_ UserFeedbackAvailability : 40|1@0+ (1.0,0.0) [0|0] "" Vector__XXX
 SG_ AudioAvailability : 41|1@0+ (1.0,0.0) [0|0] "" Vector__XXX

BO_ 1895 NAV_to_DTOOL: 8 Vector__XXX
 SG_ NAV_to_DTOOL : 7|64@0+ (1.0,0.0) [0|0] "" Vector__XXX

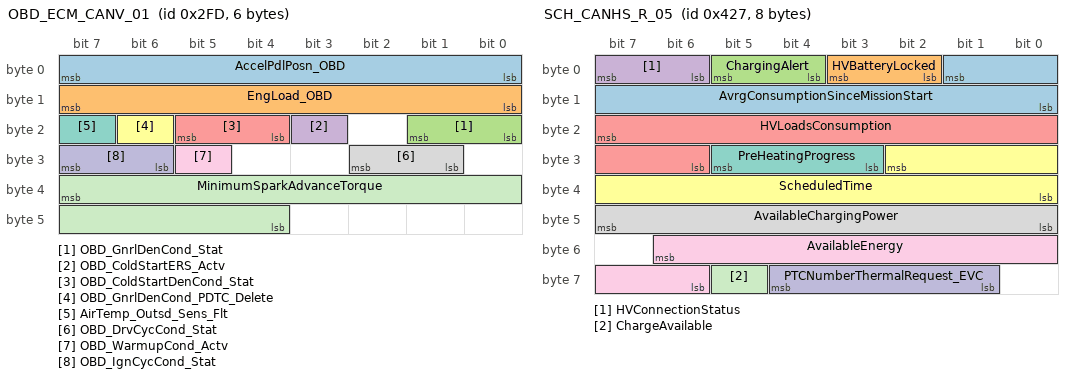
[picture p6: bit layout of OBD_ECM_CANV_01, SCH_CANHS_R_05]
BO_ 765 OBD_ECM_CANV_01: 6 Vector__XXX
 SG_ AccelPdlPosn_OBD : 7|8@0+ (0.392157,0.0) [0|0] "%" Vector__XXX
 SG_ EngLoad_OBD : 15|8@0+ (0.392157,0.0) [0|0] "%" Vector__XXX
 SG_ OBD_GnrlDenCond_Stat : 17|2@0+ (1.0,0.0) [0|0] "" Vector__XXX
 SG_ OBD_ColdStartERS_Actv : 19|1@0+ (1.0,0.0) [0|0] "" Vector__XXX
 SG_ OBD_ColdStartDenCond_Stat : 21|2@0+ (1.0,0.0) [0|0] "" Vector__XXX
 SG_ OBD_GnrlDenCond_PDTC_Delete : 22|1@0+ (1.0,0.0) [0|0] "" Vector__XXX
 SG_ AirTemp_Outsd_Sens_Flt : 23|1@0+ (1.0,0.0) [0|0] "" Vector__XXX
 SG_ OBD_DrvCycCond_Stat : 26|2@0+ (1.0,0.0) [0|0] "" Vector__XXX
 SG_ OBD_WarmupCond_Actv : 29|1@0+ (1.0,0.0) [0|0] "" Vector__XXX
 SG_ OBD_IgnCycCond_Stat : 31|2@0+ (1.0,0.0) [0|0] "" Vector__XXX
 SG_ MinimumSparkAdvanceTorque : 39|12@0- (0.5,-400.0) [0|0] "Nm" Vector__XXX

BO_ 1095 OFF_BOARD_TCU_01: 3 Vector__XXX
 SG_ TCU_PCScheduledTime1 : 5|11@0+ (1.0,0.0) [0|0] "min" Vector__XXX
 SG_ TCU_ClimPCCustomerActiv : 7|2@0+ (1.0,0.0) [0|0] "" Vector__XXX
 SG_ TCU_PCScheduledTime2 : 10|11@0+ (1.0,0.0) [0|0] "min" Vector__XXX

BO_ 1918 PEB_to_DTOOL: 8 Vector__XXX
 SG_ PEB_to_DTOOL : 7|64@0+ (1.0,0.0) [0|0] "" Vector__XXX

BO_ 1992 PLGW_to_DTOOL: 8 Vector__XXX
 SG_ PLGW_to_DTOOL : 7|64@0+ (1.0,0.0) [0|0] "" Vector__XXX

BO_ 1899 ROOF_to_DTOOL: 8 Vector__XXX
 SG_ Roof_to_DTOOL : 7|64@0+ (1.0,0.0) [0|0] "" Vector__XXX

BO_ 1842 Radio_to_DTOOL: 8 Vector__XXX
 SG_ Radio_to_DTOOL : 7|64@0+ (1.0,0.0) [0|0] "" Vector__XXX

BO_ 1485 RemoteFunctionService_BCM_Frame: 8 Vector__XXX
 SG_ RemoteFunctionService_BCM : 7|64@0+ (1.0,0.0) [0|0] "" Vector__XXX

BO_ 1509 RemoteFunctionService_TCU_Frame: 8 Vector__XXX
 SG_ RemoteFunctionService_TCU : 7|64@0+ (1.0,0.0) [0|0] "" Vector__XXX

BO_ 1849 SACHA_to_DTOOL: 8 Vector__XXX
 SG_ SACHA_to_DTOOL : 7|64@0+ (1.0,0.0) [0|0] "" Vector__XXX

BO_ 509 SCH_CANHS_R_01: 8 Vector__XXX
 SG_ DCDCLoad : 7|8@0+ (0.390625,0.0) [0|0] "%" Vector__XXX
 SG_ ElectricalLoadSheddingRequest : 9|2@0+ (1.0,0.0) [0|0] "" Vector__XXX
 SG_ ClimFanReductionRequest : 10|1@0+ (1.0,0.0) [0|0] "" Vector__XXX
 SG_ PreHeatSelectedDisplayRequest : 11|1@0+ (1.0,0.0) [0|0] "" Vector__XXX
 SG_ SCH_TrunkOpeningRequest : 13|2@0+ (1.0,0.0) [0|0] "" Vector__XXX
 SG_ SCH_Refuse_to_Sleep : 15|2@0+ (1.0,0.0) [0|0] "" Vector__XXX
 SG_ LeftTimeBeforeVehicleWakeUp : 18|11@0+ (1.0,0.0) [0|0] "" Vector__XXX
 SG_ StartPreHeatingCounter : 20|2@0+ (1.0,0.0) [0|0] "" Vector__XXX
 SG_ StopPreHeatingCounter : 22|2@0+ (1.0,0.0) [0|0] "" Vector__XXX
 SG_ BoilerOnDoorOpen : 23|1@0+ (1.0,0.0) [0|0] "" Vector__XXX
 SG_ LeftTimeToScheduledTime : 38|7@0+ (1.0,0.0) [0|0] "min" Vector__XXX
 SG_ PreHeatingActivation : 39|1@0+ (1.0,0.0) [0|0] "" Vector__XXX
 SG_ ClimAvailablePower : 47|8@0+ (25.0,0.0) [0|0] "W" Vector__XXX
 SG_ Econometer : 55|8@0- (1.0,-80.0) [0|0] "kW" Vector__XXX
 SG_ AT_GearShiftRefused : 56|1@0+ (1.0,0.0) [0|0] "" Vector__XXX
 SG_ SCH_BlowerRequest : 57|1@0+ (1.0,0.0) [0|0] "" Vector__XXX
 SG_ BMS_TiAlertDisplay : 63|1@0+ (1.0,0.0) [0|0] "" Vector__XXX

BO_ 1063 SCH_CANHS_R_05: 8 Vector__XXX
 SG_ AvrgConsumptionSinceMissionStart : 1|10@0+ (1.0,0.0) [0|0] "" Vector__XXX
 SG_ HVBatteryLocked : 3|2@0+ (1.0,0.0) [0|0] "" Vector__XXX
 SG_ ChargingAlert : 5|2@0+ (1.0,0.0) [0|0] "" Vector__XXX
 SG_ HVConnectionStatus : 7|2@0+ (1.0,0.0) [0|0] "" Vector__XXX
 SG_ HVLoadsConsumption : 23|10@0+ (10.0,0.0) [0|0] "W" Vector__XXX
 SG_ ScheduledTime : 26|11@0+ (1.0,0.0) [0|0] "" Vector__XXX
 SG_ PreHeatingProgress : 29|3@0+ (1.0,0.0) [0|0] "" Vector__XXX
 SG_ AvailableChargingPower : 47|8@0+ (0.3,0.0) [0|0] "kW" Vector__XXX
 SG_ AvailableEnergy : 54|9@0+ (0.1,0.0) [0|0] "kWh" Vector__XXX
 SG_ PTCNumberThermalRequest_EVC : 60|4@0+ (1.0,0.0) [0|0] "" Vector__XXX
 SG_ ChargeAvailable : 61|1@0+ (1.0,0.0) [0|0] "" Vector__XXX

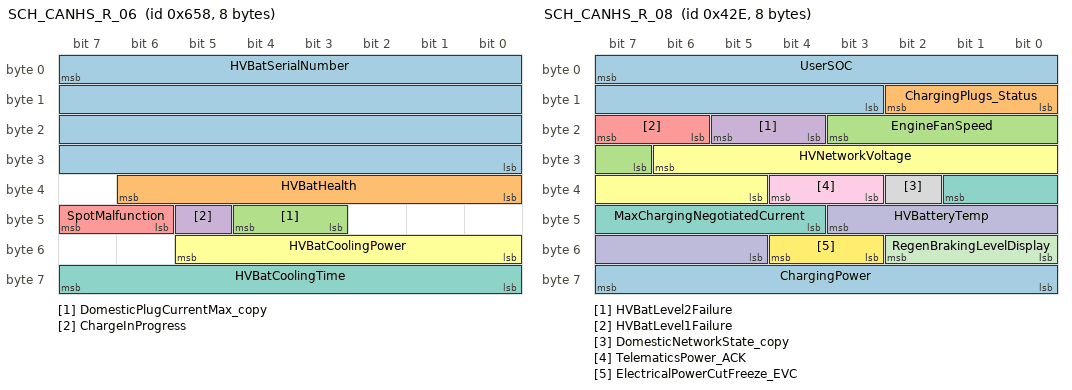
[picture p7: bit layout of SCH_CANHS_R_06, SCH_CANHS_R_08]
BO_ 1624 SCH_CANHS_R_06: 8 Vector__XXX
 SG_ HVBatSerialNumber : 7|32@0+ (1.0,0.0) [0|0] "" Vector__XXX
 SG_ HVBatHealth : 38|7@0+ (1.0,0.0) [0|0] "%" Vector__XXX
 SG_ DomesticPlugCurrentMax_copy : 44|2@0+ (1.0,0.0) [0|0] "" Vector__XXX
 SG_ ChargeInProgress : 45|1@0+ (1.0,0.0) [0|0] "" Vector__XXX
 SG_ SpotMalfunction : 47|2@0+ (1.0,0.0) [0|0] "" Vector__XXX
 SG_ HVBatCoolingPower : 53|6@0+ (1.0,0.0) [0|0] "" Vector__XXX
 SG_ HVBatCoolingTime : 63|8@0+ (1.0,0.0) [0|0] "" Vector__XXX

BO_ 1070 SCH_CANHS_R_08: 8 Vector__XXX
 SG_ UserSOC : 7|13@0+ (0.02,0.0) [0|0] "%" Vector__XXX
 SG_ ChargingPlugs_Status : 10|3@0+ (1.0,0.0) [0|0] "" Vector__XXX
 SG_ EngineFanSpeed : 19|5@0+ (5.0,0.0) [0|0] "%" Vector__XXX
 SG_ HVBatLevel2Failure : 21|2@0+ (1.0,0.0) [0|0] "" Vector__XXX
 SG_ HVBatLevel1Failure : 23|2@0+ (1.0,0.0) [0|0] "" Vector__XXX
 SG_ HVNetworkVoltage : 30|10@0+ (0.5,0.0) [0|0] "V" Vector__XXX
 SG_ MaxChargingNegotiatedCurrent : 33|6@0+ (1.0,0.0) [0|0] "A" Vector__XXX
 SG_ DomesticNetworkState_copy : 34|1@0+ (1.0,0.0) [0|0] "" Vector__XXX
 SG_ TelematicsPower_ACK : 36|2@0+ (1.0,0.0) [0|0] "" Vector__XXX
 SG_ HVBatteryTemp : 43|7@0- (1.0,-40.0) [0|0] "°C" Vector__XXX
 SG_ RegenBrakingLevelDisplay : 50|3@0+ (1.0,0.0) [0|0] "" Vector__XXX
 SG_ ElectricalPowerCutFreeze_EVC : 52|2@0+ (1.0,0.0) [0|0] "" Vector__XXX
 SG_ ChargingPower : 63|8@0+ (1.0,0.0) [0|0] "" Vector__XXX

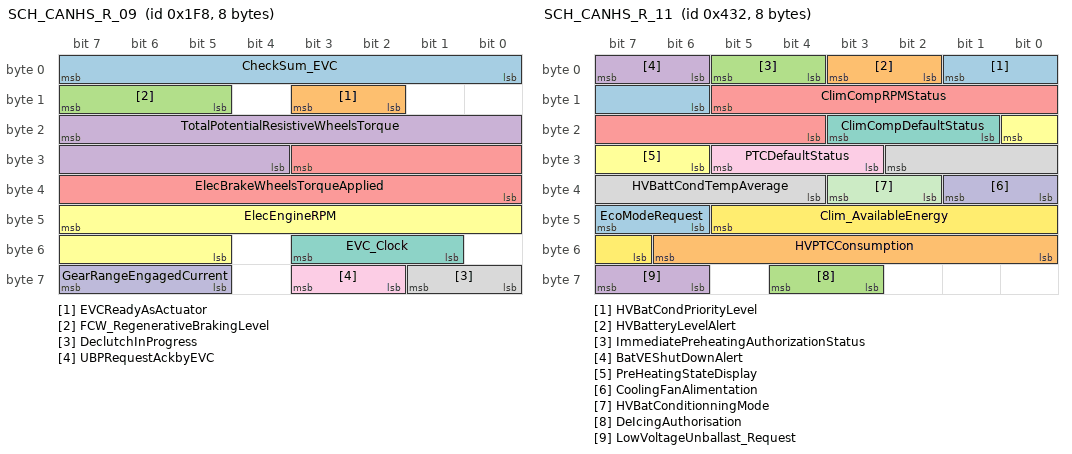
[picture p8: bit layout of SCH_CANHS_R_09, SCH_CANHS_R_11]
BO_ 504 SCH_CANHS_R_09: 8 Vector__XXX
 SG_ CheckSum_EVC : 7|8@0+ (1.0,0.0) [0|0] "" Vector__XXX
 SG_ EVCReadyAsActuator : 11|2@0+ (1.0,0.0) [0|0] "" Vector__XXX
 SG_ FCW_RegenerativeBrakingLevel : 15|3@0+ (1.0,0.0) [0|0] "" Vector__XXX
 SG_ TotalPotentialResistiveWheelsTorque : 23|12@0+ (1.0,0.0) [0|0] "" Vector__XXX
 SG_ ElecBrakeWheelsTorqueApplied : 27|12@0- (1.0,-4094.0) [0|0] "Nm" Vector__XXX
 SG_ ElecEngineRPM : 47|11@0+ (10.0,0.0) [0|0] "Rpm" Vector__XXX
 SG_ EVC_Clock : 51|3@0+ (1.0,0.0) [0|0] "" Vector__XXX
 SG_ DeclutchInProgress : 57|2@0+ (1.0,0.0) [0|0] "" Vector__XXX
 SG_ UBPRequestAckbyEVC : 59|2@0+ (1.0,0.0) [0|0] "" Vector__XXX
 SG_ GearRangeEngagedCurrent : 63|3@0+ (1.0,0.0) [0|0] "" Vector__XXX

BO_ 2047 SCH_CANHS_R_10: 5 Vector__XXX
 SG_ DistanceTotalizer_copy : 7|24@0+ (1.0,0.0) [0|0] "" Vector__XXX
 SG_ VehicleAutonomyZEVdisplay : 31|10@0+ (1.0,0.0) [0|0] "" Vector__XXX

BO_ 1074 SCH_CANHS_R_11: 8 Vector__XXX
 SG_ HVBatCondPriorityLevel : 1|4@0+ (1.0,0.0) [0|0] "" Vector__XXX
 SG_ HVBatteryLevelAlert : 3|2@0+ (1.0,0.0) [0|0] "" Vector__XXX
 SG_ ImmediatePreheatingAuthorizationStatus : 5|2@0+ (1.0,0.0) [0|0] "" Vector__XXX
 SG_ BatVEShutDownAlert : 7|2@0+ (1.0,0.0) [0|0] "" Vector__XXX
 SG_ ClimCompRPMStatus : 13|10@0+ (10.0,0.0) [0|0] "rpm" Vector__XXX
 SG_ PreHeatingStateDisplay : 16|3@0+ (1.0,0.0) [0|0] "" Vector__XXX
 SG_ ClimCompDefaultStatus : 19|3@0+ (1.0,0.0) [0|0] "" Vector__XXX
 SG_ HVBattCondTempAverage : 26|7@0+ (1.0,0.0) [0|0] "" Vector__XXX
 SG_ PTCDefaultStatus : 29|3@0+ (1.0,0.0) [0|0] "" Vector__XXX
 SG_ CoolingFanAlimentation : 33|2@0+ (1.0,0.0) [0|0] "" Vector__XXX
 SG_ HVBatConditionningMode : 35|2@0+ (1.0,0.0) [0|0] "" Vector__XXX
 SG_ Clim_AvailableEnergy : 45|7@0+ (100.0,0.0) [0|0] "Wh" Vector__XXX
 SG_ EcoModeRequest : 47|2@0+ (1.0,0.0) [0|0] "" Vector__XXX
 SG_ HVPTCConsumption : 54|7@0+ (50.0,0.0) [0|0] "W" Vector__XXX
 SG_ DeIcingAuthorisation : 60|2@0+ (1.0,0.0) [0|0] "" Vector__XXX
 SG_ LowVoltageUnballast_Request : 63|2@0+ (1.0,0.0) [0|0] "" Vector__XXX

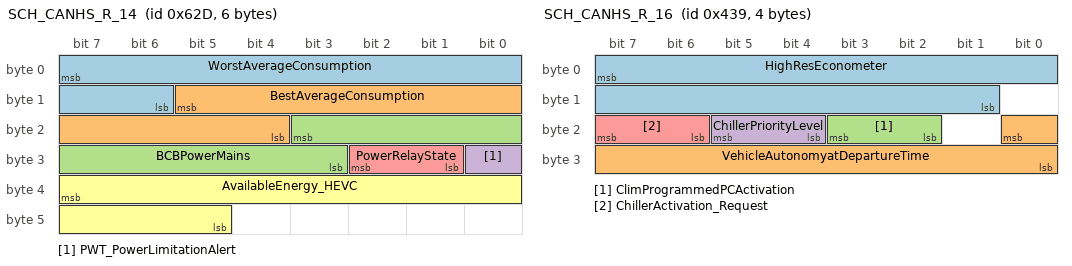
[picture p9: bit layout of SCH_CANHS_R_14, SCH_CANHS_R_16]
BO_ 1581 SCH_CANHS_R_14: 6 Vector__XXX
 SG_ WorstAverageConsumption : 7|10@0+ (0.1,0.0) [0|0] "kWh/100km" Vector__XXX
 SG_ BestAverageConsumption : 13|10@0+ (0.1,0.0) [0|0] "kWh/100km" Vector__XXX
 SG_ BCBPowerMains : 19|9@0+ (100.0,0.0) [0|0] "W" Vector__XXX
 SG_ PWT_PowerLimitationAlert : 24|1@0+ (1.0,0.0) [0|0] "" Vector__XXX
 SG_ PowerRelayState : 26|2@0+ (1.0,0.0) [0|0] "" Vector__XXX
 SG_ AvailableEnergy_HEVC : 39|11@0+ (0.05,0.0) [0|0] "KWh" Vector__XXX

BO_ 1081 SCH_CANHS_R_16: 4 Vector__XXX
 SG_ HighResEconometer : 7|15@0- (0.01,-80.0) [0|0] "KW" Vector__XXX
 SG_ VehicleAutonomyatDepartureTime : 16|9@0+ (5.0,0.0) [0|0] "km" Vector__XXX
 SG_ ClimProgrammedPCActivation : 19|2@0+ (1.0,0.0) [0|0] "" Vector__XXX
 SG_ ChillerPriorityLevel : 21|2@0+ (1.0,0.0) [0|0] "" Vector__XXX
 SG_ ChillerActivation_Request : 23|2@0+ (1.0,0.0) [0|0] "" Vector__XXX

BO_ 2028 SCH_to_DTOOL: 8 Vector__XXX
 SG_ DTOOL_to_SCH : 7|64@0+ (1.0,0.0) [0|0] "" Vector__XXX

BO_ 1981 SHIFTER_to_DTOOL: 8 Vector__XXX
 SG_ SHIFTER_to_DTOOL : 7|64@0+ (1.0,0.0) [0|0] "" Vector__XXX

BO_ 198 SWA_CANHS_RNr_01: 8 Vector__XXX
 SG_ SteeringWheelAngle : 7|16@0- (0.1,-3276.7) [0|0] "°" Vector__XXX
 SG_ SteeringWheelRotationSpeed : 23|16@0- (0.1,-3276.7) [0|0] "°/s" Vector__XXX
 SG_ SteeringWheelAngle_Offset : 39|16@0- (0.1,-3276.7) [0|0] "°" Vector__XXX
 SG_ SwaClock : 52|4@0+ (1.0,0.0) [0|0] "" Vector__XXX
 SG_ SwaSensorInternalStatus : 55|3@0+ (1.0,0.0) [0|0] "" Vector__XXX
 SG_ SwaChecksum : 63|8@0+ (1.0,0.0) [0|0] "" Vector__XXX

BO_ 2033 Scrap_AuthorizationRequestFrame: 8 Vector__XXX
 SG_ Scrap_AuthorizationRequest : 7|64@0+ (1.0,0.0) [0|0] "" Vector__XXX

BO_ 2041 Scrap_AuthorizationStatusFrame: 8 Vector__XXX
 SG_ Scrap_AuthorizationStatus : 7|64@0+ (1.0,0.0) [0|0] "" Vector__XXX

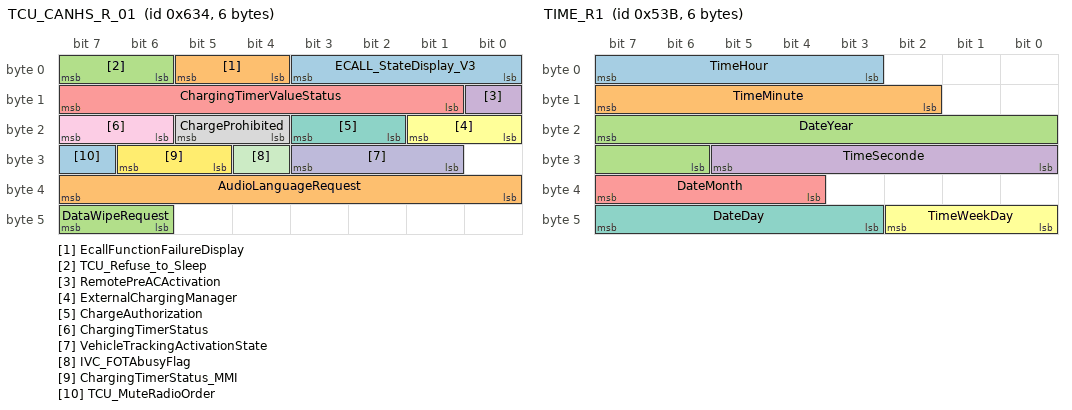
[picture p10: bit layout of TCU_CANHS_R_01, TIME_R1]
BO_ 1588 TCU_CANHS_R_01: 6 Vector__XXX
 SG_ ECALL_StateDisplay_V3 : 3|4@0+ (1.0,0.0) [0|0] "" Vector__XXX
 SG_ EcallFunctionFailureDisplay : 5|2@0+ (1.0,0.0) [0|0] "" Vector__XXX
 SG_ TCU_Refuse_to_Sleep : 7|2@0+ (1.0,0.0) [0|0] "" Vector__XXX
 SG_ RemotePreACActivation : 8|1@0+ (1.0,0.0) [0|0] "" Vector__XXX
 SG_ ChargingTimerValueStatus : 15|7@0+ (1.0,0.0) [0|0] "" Vector__XXX
 SG_ ExternalChargingManager : 17|2@0+ (1.0,0.0) [0|0] "" Vector__XXX
 SG_ ChargeAuthorization : 19|2@0+ (1.0,0.0) [0|0] "" Vector__XXX
 SG_ ChargeProhibited : 21|2@0+ (1.0,0.0) [0|0] "" Vector__XXX
 SG_ ChargingTimerStatus : 23|2@0+ (1.0,0.0) [0|0] "" Vector__XXX
 SG_ VehicleTrackingActivationState : 27|3@0+ (1.0,0.0) [0|0] "" Vector__XXX
 SG_ IVC_FOTAbusyFlag : 28|1@0+ (1.0,0.0) [0|0] "" Vector__XXX
 SG_ ChargingTimerStatus_MMI : 30|2@0+ (1.0,0.0) [0|0] "" Vector__XXX
 SG_ TCU_MuteRadioOrder : 31|1@0+ (1.0,0.0) [0|0] "" Vector__XXX
 SG_ AudioLanguageRequest : 39|8@0+ (1.0,0.0) [0|0] "" Vector__XXX
 SG_ DataWipeRequest : 47|2@0+ (1.0,0.0) [0|0] "" Vector__XXX

BO_ 1372 TCU_WakeUpFrame: 2 Vector__XXX
 SG_ TCU_WakeUp_Signal : 7|16@0+ (1.0,0.0) [0|0] "" Vector__XXX

BO_ 2010 TCU_to_DTOOL: 8 Vector__XXX
 SG_ TCU_to_DTOOL : 7|64@0+ (1.0,0.0) [0|0] "" Vector__XXX

BO_ 1339 TIME_R1: 6 Vector__XXX
 SG_ TimeHour : 7|5@0+ (1.0,0.0) [0|0] "Hour" Vector__XXX
 SG_ TimeMinute : 15|6@0+ (1.0,0.0) [0|0] "Minute" Vector__XXX
 SG_ DateYear : 23|10@0+ (1.0,0.0) [0|0] "" Vector__XXX
 SG_ TimeSeconde : 29|6@0+ (1.0,0.0) [0|0] "" Vector__XXX
 SG_ DateMonth : 39|4@0+ (1.0,0.0) [0|0] "" Vector__XXX
 SG_ TimeWeekDay : 42|3@0+ (1.0,0.0) [0|0] "" Vector__XXX
 SG_ DateDay : 47|5@0+ (1.0,0.0) [0|0] "" Vector__XXX

BO_ 525 TORQUE_AT_CANHS_D_01: 8 Vector__XXX
 SG_ CrankingAuthorisation_AT_Copy : 3|2@0+ (1.0,0.0) [0|0] "" Vector__XXX
 SG_ TransmRangeEngaged_Current_Copy : 7|4@0+ (1.0,0.0) [0|0] "" Vector__XXX
 SG_ AT_TorqueLosses_Copy : 15|8@0+ (0.5,0.0) [0|0] "Nm" Vector__XXX
 SG_ Clock_TORQUE_AT_D_01 : 51|4@0+ (1.0,0.0) [0|0] "" Vector__XXX
 SG_ CRC_TORQUE_AT_D_01 : 63|8@0+ (1.0,0.0) [0|0] "" Vector__XXX

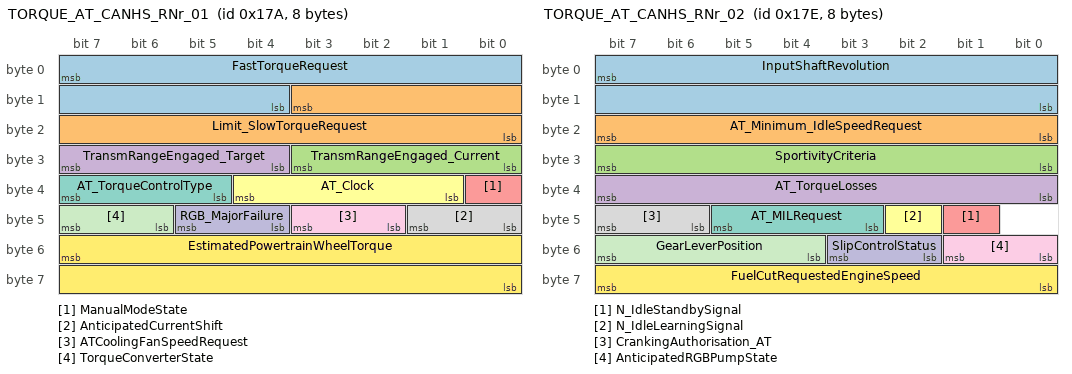
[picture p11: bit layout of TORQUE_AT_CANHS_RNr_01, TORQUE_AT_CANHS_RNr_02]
BO_ 378 TORQUE_AT_CANHS_RNr_01: 8 Vector__XXX
 SG_ FastTorqueRequest : 7|12@0- (0.5,-400.0) [0|0] "Nm" Vector__XXX
 SG_ Limit_SlowTorqueRequest : 11|12@0- (0.5,-400.0) [0|0] "Nm" Vector__XXX
 SG_ TransmRangeEngaged_Current : 27|4@0+ (1.0,0.0) [0|0] "" Vector__XXX
 SG_ TransmRangeEngaged_Target : 31|4@0+ (1.0,0.0) [0|0] "" Vector__XXX
 SG_ ManualModeState : 32|1@0+ (1.0,0.0) [0|0] "" Vector__XXX
 SG_ AT_Clock : 36|4@0+ (1.0,0.0) [0|0] "" Vector__XXX
 SG_ AT_TorqueControlType : 39|3@0+ (1.0,0.0) [0|0] "" Vector__XXX
 SG_ AnticipatedCurrentShift : 41|2@0+ (1.0,0.0) [0|0] "" Vector__XXX
 SG_ ATCoolingFanSpeedRequest : 43|2@0+ (1.0,0.0) [0|0] "" Vector__XXX
 SG_ RGB_MajorFailure : 45|2@0+ (1.0,0.0) [0|0] "" Vector__XXX
 SG_ TorqueConverterState : 47|2@0+ (1.0,0.0) [0|0] "" Vector__XXX
 SG_ EstimatedPowertrainWheelTorque : 55|16@0- (0.5,-6400.0) [0|0] "Nm" Vector__XXX

BO_ 382 TORQUE_AT_CANHS_RNr_02: 8 Vector__XXX
 SG_ InputShaftRevolution : 7|16@0+ (1.0,0.0) [0|0] "rpm" Vector__XXX
 SG_ AT_Minimum_IdleSpeedRequest : 23|8@0+ (8.0,0.0) [0|0] "rpm" Vector__XXX
 SG_ SportivityCriteria : 31|8@0+ (1.0,0.0) [0|0] "" Vector__XXX
 SG_ AT_TorqueLosses : 39|8@0+ (0.5,0.0) [0|0] "Nm" Vector__XXX
 SG_ N_IdleStandbySignal : 41|1@0+ (1.0,0.0) [0|0] "" Vector__XXX
 SG_ N_IdleLearningSignal : 42|1@0+ (1.0,0.0) [0|0] "" Vector__XXX
 SG_ AT_MILRequest : 45|3@0+ (1.0,0.0) [0|0] "" Vector__XXX
 SG_ CrankingAuthorisation_AT : 47|2@0+ (1.0,0.0) [0|0] "" Vector__XXX
 SG_ AnticipatedRGBPumpState : 49|2@0+ (1.0,0.0) [0|0] "" Vector__XXX
 SG_ SlipControlStatus : 51|2@0+ (1.0,0.0) [0|0] "" Vector__XXX
 SG_ GearLeverPosition : 55|4@0+ (1.0,0.0) [0|0] "" Vector__XXX
 SG_ FuelCutRequestedEngineSpeed : 63|8@0+ (1.0,0.0) [0|0] "" Vector__XXX

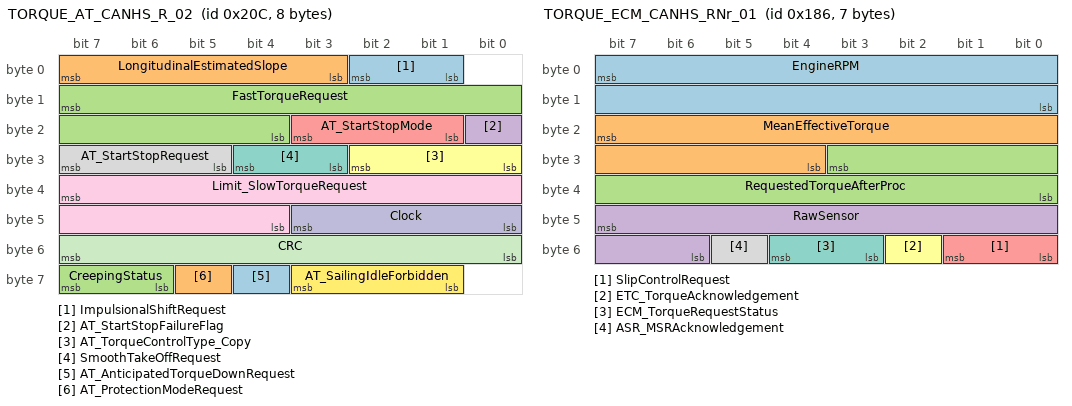
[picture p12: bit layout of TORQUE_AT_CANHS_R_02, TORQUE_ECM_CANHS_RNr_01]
BO_ 524 TORQUE_AT_CANHS_R_02: 8 Vector__XXX
 SG_ ImpulsionalShiftRequest : 2|2@0+ (1.0,0.0) [0|0] "" Vector__XXX
 SG_ LongitudinalEstimatedSlope : 7|5@0+ (1.0,0.0) [0|0] "" Vector__XXX
 SG_ FastTorqueRequest : 15|12@0- (0.5,-400.0) [0|0] "Nm" Vector__XXX
 SG_ AT_StartStopFailureFlag : 16|1@0+ (1.0,0.0) [0|0] "" Vector__XXX
 SG_ AT_StartStopMode : 19|3@0+ (1.0,0.0) [0|0] "" Vector__XXX
 SG_ AT_TorqueControlType_Copy : 26|3@0+ (1.0,0.0) [0|0] "" Vector__XXX
 SG_ SmoothTakeOffRequest : 28|2@0+ (1.0,0.0) [0|0] "" Vector__XXX
 SG_ AT_StartStopRequest : 31|3@0+ (1.0,0.0) [0|0] "" Vector__XXX
 SG_ Limit_SlowTorqueRequest : 39|12@0- (0.5,-400.0) [0|0] "Nm" Vector__XXX
 SG_ Clock : 43|4@0+ (1.0,0.0) [0|0] "" Vector__XXX
 SG_ CRC : 55|8@0+ (1.0,0.0) [0|0] "" Vector__XXX
 SG_ AT_SailingIdleForbidden : 59|3@0+ (1.0,0.0) [0|0] "" Vector__XXX
 SG_ AT_AnticipatedTorqueDownRequest : 60|1@0+ (1.0,0.0) [0|0] "" Vector__XXX
 SG_ AT_ProtectionModeRequest : 61|1@0+ (1.0,0.0) [0|0] "" Vector__XXX
 SG_ CreepingStatus : 63|2@0+ (1.0,0.0) [0|0] "" Vector__XXX

BO_ 390 TORQUE_ECM_CANHS_RNr_01: 7 Vector__XXX
 SG_ EngineRPM : 7|16@0+ (0.125,0.0) [0|0] "rpm" Vector__XXX
 SG_ MeanEffectiveTorque : 23|12@0- (0.5,-400.0) [0|0] "Nm" Vector__XXX
 SG_ RequestedTorqueAfterProc : 27|12@0- (0.5,-400.0) [0|0] "Nm" Vector__XXX
 SG_ RawSensor : 47|10@0+ (0.125,0.0) [0|0] "%" Vector__XXX
 SG_ SlipControlRequest : 49|2@0+ (1.0,0.0) [0|0] "" Vector__XXX
 SG_ ETC_TorqueAcknowledgement : 50|1@0+ (1.0,0.0) [0|0] "" Vector__XXX
 SG_ ECM_TorqueRequestStatus : 52|2@0+ (1.0,0.0) [0|0] "" Vector__XXX
 SG_ ASR_MSRAcknowledgement : 53|1@0+ (1.0,0.0) [0|0] "" Vector__XXX

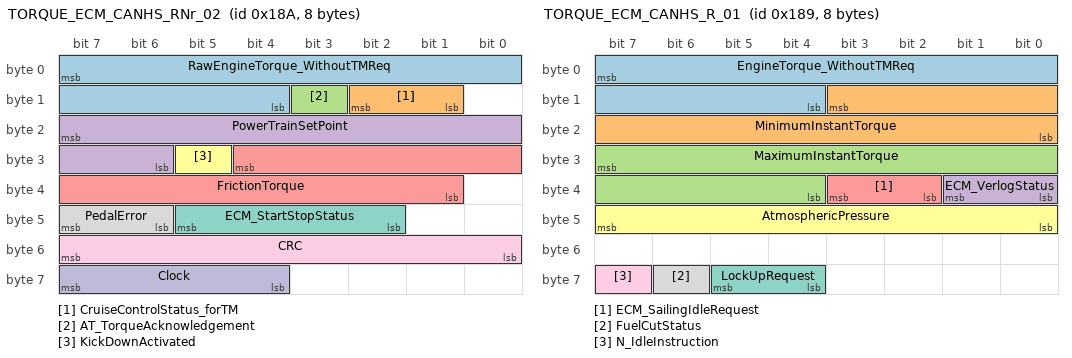
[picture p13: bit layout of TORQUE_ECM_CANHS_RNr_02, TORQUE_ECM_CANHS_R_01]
BO_ 394 TORQUE_ECM_CANHS_RNr_02: 8 Vector__XXX
 SG_ RawEngineTorque_WithoutTMReq : 7|12@0- (0.5,-400.0) [0|0] "Nm" Vector__XXX
 SG_ CruiseControlStatus_forTM : 10|2@0+ (1.0,0.0) [0|0] "" Vector__XXX
 SG_ AT_TorqueAcknowledgement : 11|1@0+ (1.0,0.0) [0|0] "" Vector__XXX
 SG_ PowerTrainSetPoint : 23|10@0+ (0.125,0.0) [0|0] "%" Vector__XXX
 SG_ FrictionTorque : 28|12@0- (0.5,-400.0) [0|0] "Nm" Vector__XXX
 SG_ KickDownActivated : 29|1@0+ (1.0,0.0) [0|0] "" Vector__XXX
 SG_ ECM_StartStopStatus : 45|4@0+ (1.0,0.0) [0|0] "" Vector__XXX
 SG_ PedalError : 47|2@0+ (1.0,0.0) [0|0] "" Vector__XXX
 SG_ CRC : 55|8@0+ (1.0,0.0) [0|0] "" Vector__XXX
 SG_ Clock : 63|4@0+ (1.0,0.0) [0|0] "" Vector__XXX

BO_ 393 TORQUE_ECM_CANHS_R_01: 8 Vector__XXX
 SG_ EngineTorque_WithoutTMReq : 7|12@0- (0.5,-400.0) [0|0] "Nm" Vector__XXX
 SG_ MinimumInstantTorque : 11|12@0- (0.5,-400.0) [0|0] "Nm" Vector__XXX
 SG_ MaximumInstantTorque : 31|12@0- (0.5,-400.0) [0|0] "Nm" Vector__XXX
 SG_ ECM_VerlogStatus : 33|2@0+ (1.0,0.0) [0|0] "" Vector__XXX
 SG_ ECM_SailingIdleRequest : 35|2@0+ (1.0,0.0) [0|0] "" Vector__XXX
 SG_ AtmosphericPressure : 47|8@0+ (2.0,600.0) [0|0] "hPa" Vector__XXX
 SG_ LockUpRequest : 61|2@0+ (1.0,0.0) [0|0] "" Vector__XXX
 SG_ FuelCutStatus : 62|1@0+ (1.0,0.0) [0|0] "" Vector__XXX
 SG_ N_IdleInstruction : 63|1@0+ (1.0,0.0) [0|0] "" Vector__XXX

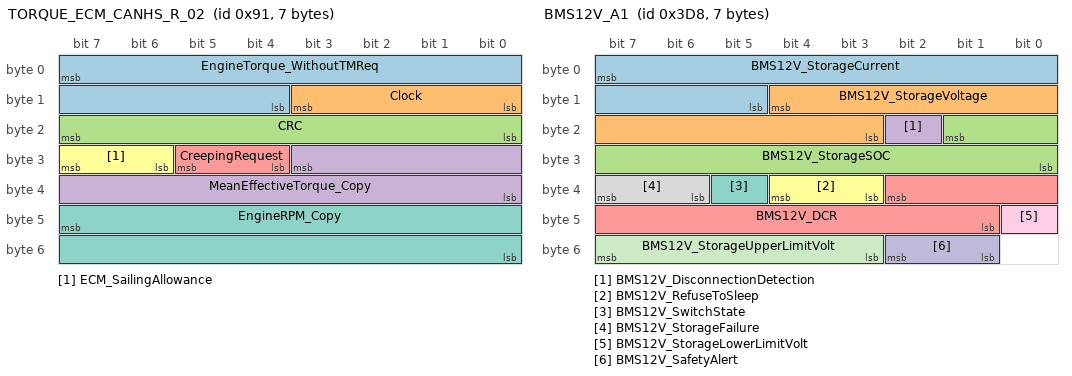
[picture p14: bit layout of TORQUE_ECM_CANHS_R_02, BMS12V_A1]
BO_ 145 TORQUE_ECM_CANHS_R_02: 7 Vector__XXX
 SG_ EngineTorque_WithoutTMReq : 7|12@0- (0.5,-400.0) [0|0] "Nm" Vector__XXX
 SG_ Clock : 11|4@0+ (1.0,0.0) [0|0] "" Vector__XXX
 SG_ CRC : 23|8@0+ (1.0,0.0) [0|0] "" Vector__XXX
 SG_ MeanEffectiveTorque_Copy : 27|12@0- (0.5,-400.0) [0|0] "Nm" Vector__XXX
 SG_ CreepingRequest : 29|2@0+ (1.0,0.0) [0|0] "" Vector__XXX
 SG_ ECM_SailingAllowance : 31|2@0+ (1.0,0.0) [0|0] "" Vector__XXX
 SG_ EngineRPM_Copy : 47|16@0+ (0.125,0.0) [0|0] "Tr/min" Vector__XXX

BO_ 1397 TRACKER_BCM_CANHS_R_01: 2 Vector__XXX
 SG_ TrackerBCM2 : 5|10@0+ (1.0,0.0) [0|0] "" Vector__XXX
 SG_ TrackerBCM1 : 7|2@0+ (1.0,0.0) [0|0] "" Vector__XXX
 SG_ TrackerBCM3 : 11|2@0+ (1.0,0.0) [0|0] "" Vector__XXX

BO_ 1398 TRACKER_TCU_CANHS_R_01: 2 Vector__XXX
 SG_ TrackerTCU2 : 5|10@0+ (1.0,0.0) [0|0] "" Vector__XXX
 SG_ TrackerTCU1 : 7|2@0+ (1.0,0.0) [0|0] "" Vector__XXX
 SG_ TrackerTCU3 : 11|2@0+ (1.0,0.0) [0|0] "" Vector__XXX

BO_ 1901 USM_to_DTOOL: 8 Vector__XXX
 SG_ USM_to_DTOOL : 7|64@0+ (1.0,0.0) [0|0] "" Vector__XXX

BO_ 1637 UserSetPref_CANHS_R_01: 8 Vector__XXX
 SG_ EasyAccessActivationRequest : 1|2@0+ (1.0,0.0) [0|0] "" Vector__XXX
 SG_ AutoMirrorFoldingActivationReq : 3|2@0+ (1.0,0.0) [0|0] "" Vector__XXX
 SG_ SingleDoorOpeningActivationReq : 5|2@0+ (1.0,0.0) [0|0] "" Vector__XXX
 SG_ AutoLockUpActivationRequest : 7|2@0+ (1.0,0.0) [0|0] "" Vector__XXX
 SG_ FrontParkAssistVolumeReq : 10|3@0+ (1.0,0.0) [0|0] "" Vector__XXX
 SG_ FrontParkAssistActivationReq : 12|2@0+ (1.0,0.0) [0|0] "" Vector__XXX
 SG_ SailingIdleActivationRequest : 15|2@0+ (1.0,0.0) [0|0] "" Vector__XXX
 SG_ DRLActivationRequest : 18|2@0+ (1.0,0.0) [0|0] "" Vector__XXX
 SG_ RearParkAssistVolumeReq : 21|3@0+ (1.0,0.0) [0|0] "" Vector__XXX
 SG_ RearParkAssistActivationReq : 23|2@0+ (1.0,0.0) [0|0] "" Vector__XXX
 SG_ LDW_TimeToAlertRequest : 25|2@0+ (1.0,0.0) [0|0] "" Vector__XXX
 SG_ AutoRearWiperActivationRequest : 27|2@0+ (1.0,0.0) [0|0] "" Vector__XXX
 SG_ LanguageConfigurationRequest : 31|4@0+ (1.0,0.0) [0|0] "" Vector__XXX
 SG_ LanguageFamilyTypeRequest : 32|1@0+ (1.0,0.0) [0|0] "" Vector__XXX
 SG_ AdvisorEcoLightingActivationRequest : 34|2@0+ (1.0,0.0) [0|0] "" Vector__XXX
 SG_ AHL_ActivationRequest : 36|2@0+ (1.0,0.0) [0|0] "" Vector__XXX
 SG_ LDW_SoundLevelRequest : 39|3@0+ (1.0,0.0) [0|0] "" Vector__XXX
 SG_ ChargingTimerValueRequest : 45|7@0+ (1.0,0.0) [0|0] "" Vector__XXX
 SG_ ChargingTimerRequest : 47|2@0+ (1.0,0.0) [0|0] "" Vector__XXX
 SG_ FKP_ActivationRequest : 49|2@0+ (1.0,0.0) [0|0] "" Vector__XXX
 SG_ BSW_ActivationRequest : 51|2@0+ (1.0,0.0) [0|0] "" Vector__XXX
 SG_ HFP_DefaultManeuverTypeRequest : 54|3@0+ (1.0,0.0) [0|0] "" Vector__XXX
 SG_ AmbientLightingPatternRequest2 : 57|2@0+ (1.0,0.0) [0|0] "" Vector__XXX
 SG_ IKeyAccessActivationRequest : 59|2@0+ (1.0,0.0) [0|0] "" Vector__XXX
 SG_ BuzzerWAC_ActivationRequest : 61|2@0+ (1.0,0.0) [0|0] "" Vector__XXX
 SG_ WAC_APRUN_ActivationRequest : 63|2@0+ (1.0,0.0) [0|0] "" Vector__XXX

BO_ 1889 VSP_to_DTOOL: 8 Vector__XXX
 SG_ VSP_to_DTOOL : 7|64@0+ (1.0,0.0) [0|0] "" Vector__XXX

BO_ 1695 VehicleID_CANHS_R_01: 4 Vector__XXX
 SG_ VehicleID : 7|32@0+ (1.0,0.0) [0|0] "" Vector__XXX

BO_ 2001 WSU_to_DTOOL: 8 Vector__XXX
 SG_ WSU_to_DTOOL : 7|64@0+ (1.0,0.0) [0|0] "" Vector__XXX

BO_ 984 BMS12V_A1: 7 Vector__XXX // Original Name: VehicleID_CANHS_R_01
 SG_ BMS12V_StorageCurrent : 7|11@0- (0.25,-150.0) [0|0] "A" Vector__XXX // Original Name: VehicleID
 SG_ BMS12V_StorageVoltage : 12|10@0+ (0.01,9.0) [0|0] "V" Vector__XXX // Original Name: VehicleID
 SG_ BMS12V_StorageSOC : 17|10@0+ (1.0,0.0) [0|0] "" Vector__XXX // Original Name: VehicleID
 SG_ BMS12V_DisconnectionDetection : 18|1@0+ (1.0,0.0) [0|0] "" Vector__XXX // Original Name: VehicleID
 SG_ BMS12V_DCR : 34|10@0+ (0.04,0.0) [0|0] "mOhm" Vector__XXX // Original Name: VehicleID
 SG_ BMS12V_RefuseToSleep : 36|2@0+ (1.0,0.0) [0|0] "" Vector__XXX // Original Name: VehicleID
 SG_ BMS12V_SwitchState : 37|1@0+ (1.0,0.0) [0|0] "" Vector__XXX // Original Name: VehicleID
 SG_ BMS12V_StorageFailure : 39|2@0+ (1.0,0.0) [0|0] "" Vector__XXX // Original Name: VehicleID
 SG_ BMS12V_StorageLowerLimitVolt : 40|1@0+ (1.0,0.0) [0|0] "" Vector__XXX // Original Name: VehicleID
 SG_ BMS12V_SafetyAlert : 50|2@0+ (1.0,0.0) [0|0] "" Vector__XXX // Original Name: VehicleID
 SG_ BMS12V_StorageUpperLimitVolt : 55|5@0+ (0.1,13.5) [0|0] "V" Vector__XXX // Original Name: VehicleID

BO_ 1725 BMS12V_A2: 3 Vector__XXX // Original Name: VehicleID_CANHS_R_01
 SG_ BMS12V_StorageTemperature : 7|8@0- (0.5,-45.0) [0|0] "°C" Vector__XXX // Original Name: VehicleID
 SG_ BMS12V_StorageSOH_C : 15|7@0+ (1.0,0.0) [0|0] "%" Vector__XXX // Original Name: VehicleID
 SG_ BMS12V_StorageSOH_R : 21|6@0+ (1.0,100.0) [0|0] "%" Vector__XXX // Original Name: VehicleID

BO_ 1242 BMS12V_A3: 3 Vector__XXX // Original Name: VehicleID_CANHS_R_01
 SG_ CRC_BMS12V_A3 : 7|8@0+ (1.0,0.0) [0|0] "" Vector__XXX // Original Name: VehicleID
 SG_ BMS12V_StorageSOC : 11|10@0+ (1.0,0.0) [0|0] "" Vector__XXX // Original Name: VehicleID
 SG_ Clock_BMS12V_A3 : 15|4@0+ (1.0,0.0) [0|0] "" Vector__XXX // Original Name: VehicleID
 SG_ BMS12V_SwitchState : 17|1@0+ (1.0,0.0) [0|0] "" Vector__XXX // Original Name: VehicleID

BO_ 2564485596 BMS2_to_DTOOLextd: 8 Vector__XXX // Original Name: VehicleID_CANHS_R_01
 SG_ BMS2_to_DTOOLextd : 7|64@0+ (1.0,0.0) [0|0] "" Vector__XXX // Original Name: VehicleID

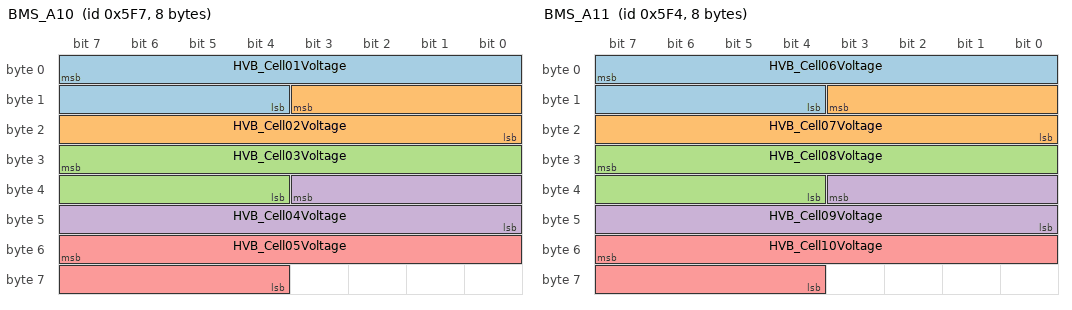
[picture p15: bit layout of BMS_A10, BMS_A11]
BO_ 1527 BMS_A10: 8 Vector__XXX // Original Name: VehicleID_CANHS_R_01
 SG_ HVB_Cell01Voltage : 7|12@0+ (0.001,2.0) [0|0] "V" Vector__XXX // Original Name: VehicleID
 SG_ HVB_Cell02Voltage : 11|12@0+ (0.001,2.0) [0|0] "V" Vector__XXX // Original Name: VehicleID
 SG_ HVB_Cell03Voltage : 31|12@0+ (0.001,2.0) [0|0] "V" Vector__XXX // Original Name: VehicleID
 SG_ HVB_Cell04Voltage : 35|12@0+ (0.001,2.0) [0|0] "V" Vector__XXX // Original Name: VehicleID
 SG_ HVB_Cell05Voltage : 55|12@0+ (0.001,2.0) [0|0] "V" Vector__XXX // Original Name: VehicleID

BO_ 1524 BMS_A11: 8 Vector__XXX // Original Name: VehicleID_CANHS_R_01
 SG_ HVB_Cell06Voltage : 7|12@0+ (0.001,2.0) [0|0] "V" Vector__XXX // Original Name: VehicleID
 SG_ HVB_Cell07Voltage : 11|12@0+ (0.001,2.0) [0|0] "V" Vector__XXX // Original Name: VehicleID
 SG_ HVB_Cell08Voltage : 31|12@0+ (0.001,2.0) [0|0] "V" Vector__XXX // Original Name: VehicleID
 SG_ HVB_Cell09Voltage : 35|12@0+ (0.001,2.0) [0|0] "V" Vector__XXX // Original Name: VehicleID
 SG_ HVB_Cell10Voltage : 55|12@0+ (0.001,2.0) [0|0] "V" Vector__XXX // Original Name: VehicleID

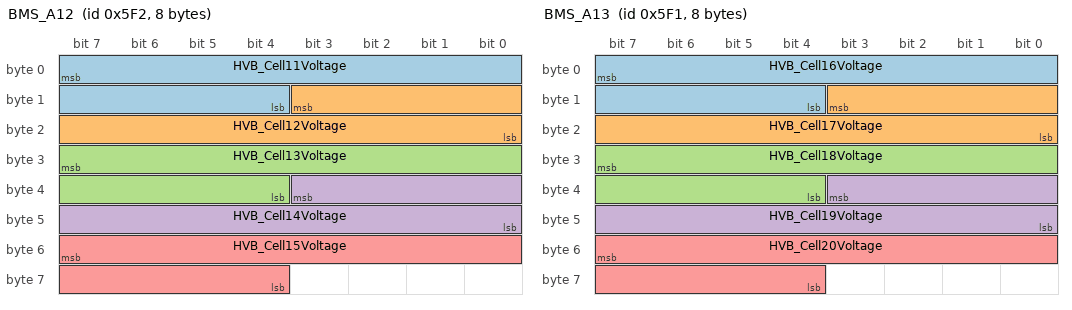
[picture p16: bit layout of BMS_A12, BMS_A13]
BO_ 1522 BMS_A12: 8 Vector__XXX // Original Name: VehicleID_CANHS_R_01
 SG_ HVB_Cell11Voltage : 7|12@0+ (0.001,2.0) [0|0] "V" Vector__XXX // Original Name: VehicleID
 SG_ HVB_Cell12Voltage : 11|12@0+ (0.001,2.0) [0|0] "V" Vector__XXX // Original Name: VehicleID
 SG_ HVB_Cell13Voltage : 31|12@0+ (0.001,2.0) [0|0] "V" Vector__XXX // Original Name: VehicleID
 SG_ HVB_Cell14Voltage : 35|12@0+ (0.001,2.0) [0|0] "V" Vector__XXX // Original Name: VehicleID
 SG_ HVB_Cell15Voltage : 55|12@0+ (0.001,2.0) [0|0] "V" Vector__XXX // Original Name: VehicleID

BO_ 1521 BMS_A13: 8 Vector__XXX // Original Name: VehicleID_CANHS_R_01
 SG_ HVB_Cell16Voltage : 7|12@0+ (0.001,2.0) [0|0] "V" Vector__XXX // Original Name: VehicleID
 SG_ HVB_Cell17Voltage : 11|12@0+ (0.001,2.0) [0|0] "V" Vector__XXX // Original Name: VehicleID
 SG_ HVB_Cell18Voltage : 31|12@0+ (0.001,2.0) [0|0] "V" Vector__XXX // Original Name: VehicleID
 SG_ HVB_Cell19Voltage : 35|12@0+ (0.001,2.0) [0|0] "V" Vector__XXX // Original Name: VehicleID
 SG_ HVB_Cell20Voltage : 55|12@0+ (0.001,2.0) [0|0] "V" Vector__XXX // Original Name: VehicleID

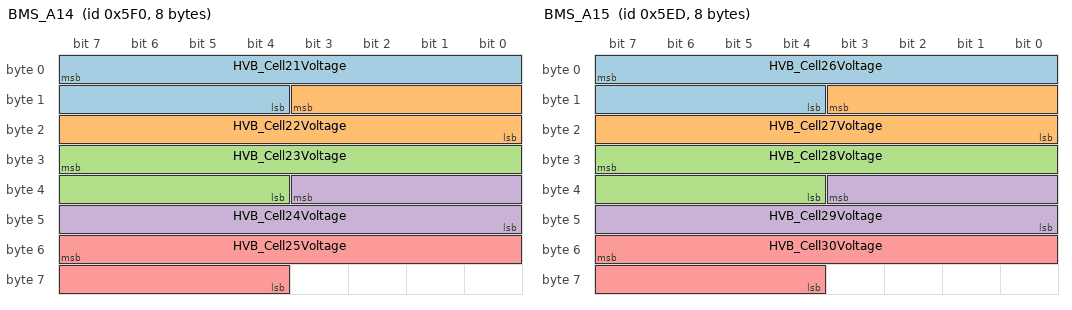
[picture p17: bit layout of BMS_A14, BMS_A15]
BO_ 1520 BMS_A14: 8 Vector__XXX // Original Name: VehicleID_CANHS_R_01
 SG_ HVB_Cell21Voltage : 7|12@0+ (0.001,2.0) [0|0] "V" Vector__XXX // Original Name: VehicleID
 SG_ HVB_Cell22Voltage : 11|12@0+ (0.001,2.0) [0|0] "V" Vector__XXX // Original Name: VehicleID
 SG_ HVB_Cell23Voltage : 31|12@0+ (0.001,2.0) [0|0] "V" Vector__XXX // Original Name: VehicleID
 SG_ HVB_Cell24Voltage : 35|12@0+ (0.001,2.0) [0|0] "V" Vector__XXX // Original Name: VehicleID
 SG_ HVB_Cell25Voltage : 55|12@0+ (0.001,2.0) [0|0] "V" Vector__XXX // Original Name: VehicleID

BO_ 1517 BMS_A15: 8 Vector__XXX // Original Name: VehicleID_CANHS_R_01
 SG_ HVB_Cell26Voltage : 7|12@0+ (0.001,2.0) [0|0] "V" Vector__XXX // Original Name: VehicleID
 SG_ HVB_Cell27Voltage : 11|12@0+ (0.001,2.0) [0|0] "V" Vector__XXX // Original Name: VehicleID
 SG_ HVB_Cell28Voltage : 31|12@0+ (0.001,2.0) [0|0] "V" Vector__XXX // Original Name: VehicleID
 SG_ HVB_Cell29Voltage : 35|12@0+ (0.001,2.0) [0|0] "V" Vector__XXX // Original Name: VehicleID
 SG_ HVB_Cell30Voltage : 55|12@0+ (0.001,2.0) [0|0] "V" Vector__XXX // Original Name: VehicleID

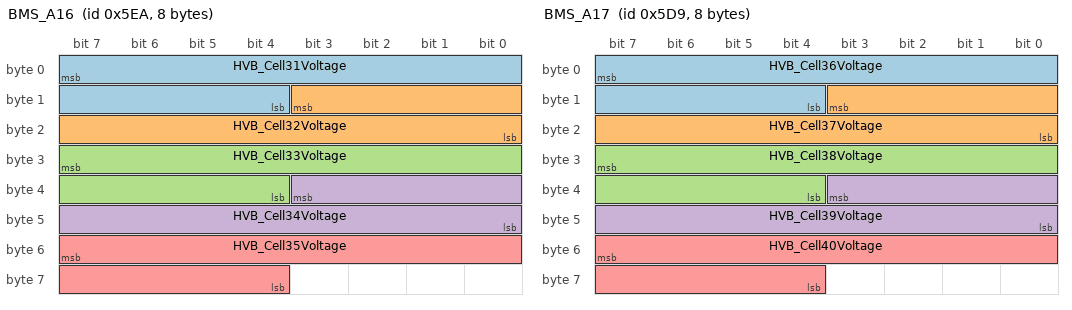
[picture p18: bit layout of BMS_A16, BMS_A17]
BO_ 1514 BMS_A16: 8 Vector__XXX // Original Name: VehicleID_CANHS_R_01
 SG_ HVB_Cell31Voltage : 7|12@0+ (0.001,2.0) [0|0] "V" Vector__XXX // Original Name: VehicleID
 SG_ HVB_Cell32Voltage : 11|12@0+ (0.001,2.0) [0|0] "V" Vector__XXX // Original Name: VehicleID
 SG_ HVB_Cell33Voltage : 31|12@0+ (0.001,2.0) [0|0] "V" Vector__XXX // Original Name: VehicleID
 SG_ HVB_Cell34Voltage : 35|12@0+ (0.001,2.0) [0|0] "V" Vector__XXX // Original Name: VehicleID
 SG_ HVB_Cell35Voltage : 55|12@0+ (0.001,2.0) [0|0] "V" Vector__XXX // Original Name: VehicleID

BO_ 1497 BMS_A17: 8 Vector__XXX // Original Name: VehicleID_CANHS_R_01
 SG_ HVB_Cell36Voltage : 7|12@0+ (0.001,2.0) [0|0] "V" Vector__XXX // Original Name: VehicleID
 SG_ HVB_Cell37Voltage : 11|12@0+ (0.001,2.0) [0|0] "V" Vector__XXX // Original Name: VehicleID
 SG_ HVB_Cell38Voltage : 31|12@0+ (0.001,2.0) [0|0] "V" Vector__XXX // Original Name: VehicleID
 SG_ HVB_Cell39Voltage : 35|12@0+ (0.001,2.0) [0|0] "V" Vector__XXX // Original Name: VehicleID
 SG_ HVB_Cell40Voltage : 55|12@0+ (0.001,2.0) [0|0] "V" Vector__XXX // Original Name: VehicleID

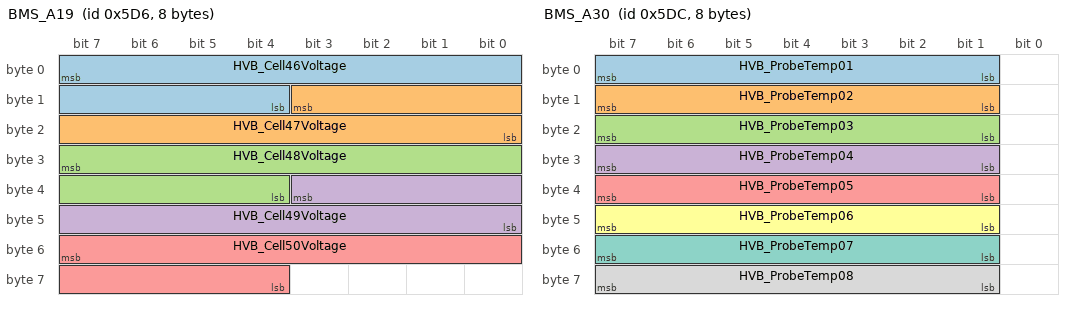
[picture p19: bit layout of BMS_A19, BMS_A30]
BO_ 1494 BMS_A19: 8 Vector__XXX // Original Name: VehicleID_CANHS_R_01
 SG_ HVB_Cell46Voltage : 7|12@0+ (0.001,2.0) [0|0] "V" Vector__XXX // Original Name: VehicleID
 SG_ HVB_Cell47Voltage : 11|12@0+ (0.001,2.0) [0|0] "V" Vector__XXX // Original Name: VehicleID
 SG_ HVB_Cell48Voltage : 31|12@0+ (0.001,2.0) [0|0] "V" Vector__XXX // Original Name: VehicleID
 SG_ HVB_Cell49Voltage : 35|12@0+ (0.001,2.0) [0|0] "V" Vector__XXX // Original Name: VehicleID
 SG_ HVB_Cell50Voltage : 55|12@0+ (0.001,2.0) [0|0] "V" Vector__XXX // Original Name: VehicleID

BO_ 1484 BMS_A20: 8 Vector__XXX // Original Name: VehicleID_CANHS_R_01
 SG_ HVB_Cell51Voltage : 7|12@0+ (0.001,2.0) [0|0] "V" Vector__XXX // Original Name: VehicleID
 SG_ HVB_Cell52Voltage : 11|12@0+ (0.001,2.0) [0|0] "V" Vector__XXX // Original Name: VehicleID
 SG_ HVB_Cell53Voltage : 31|12@0+ (0.001,2.0) [0|0] "V" Vector__XXX // Original Name: VehicleID
 SG_ HVB_Cell54Voltage : 35|12@0+ (0.001,2.0) [0|0] "V" Vector__XXX // Original Name: VehicleID
 SG_ HVB_Cell55Voltage : 55|12@0+ (0.001,2.0) [0|0] "V" Vector__XXX // Original Name: VehicleID

BO_ 1483 BMS_A21: 8 Vector__XXX // Original Name: VehicleID_CANHS_R_01
 SG_ HVB_Cell56Voltage : 7|12@0+ (0.001,2.0) [0|0] "V" Vector__XXX // Original Name: VehicleID
 SG_ HVB_Cell57Voltage : 11|12@0+ (0.001,2.0) [0|0] "V" Vector__XXX // Original Name: VehicleID
 SG_ HVB_Cell58Voltage : 31|12@0+ (0.001,2.0) [0|0] "V" Vector__XXX // Original Name: VehicleID
 SG_ HVB_Cell59Voltage : 35|12@0+ (0.001,2.0) [0|0] "V" Vector__XXX // Original Name: VehicleID
 SG_ HVB_Cell60Voltage : 55|12@0+ (0.001,2.0) [0|0] "V" Vector__XXX // Original Name: VehicleID

BO_ 1481 BMS_A22: 8 Vector__XXX // Original Name: VehicleID_CANHS_R_01
 SG_ HVB_Cell61Voltage : 7|12@0+ (0.001,2.0) [0|0] "V" Vector__XXX // Original Name: VehicleID
 SG_ HVB_Cell62Voltage : 11|12@0+ (0.001,2.0) [0|0] "V" Vector__XXX // Original Name: VehicleID
 SG_ HVB_Cell63Voltage : 31|12@0+ (0.001,2.0) [0|0] "V" Vector__XXX // Original Name: VehicleID
 SG_ HVB_Cell64Voltage : 35|12@0+ (0.001,2.0) [0|0] "V" Vector__XXX // Original Name: VehicleID
 SG_ HVB_Cell65Voltage : 55|12@0+ (0.001,2.0) [0|0] "V" Vector__XXX // Original Name: VehicleID

BO_ 1463 BMS_A23: 8 Vector__XXX // Original Name: VehicleID_CANHS_R_01
 SG_ HVB_Cell66Voltage : 7|12@0+ (0.001,2.0) [0|0] "V" Vector__XXX // Original Name: VehicleID
 SG_ HVB_Cell67Voltage : 11|12@0+ (0.001,2.0) [0|0] "V" Vector__XXX // Original Name: VehicleID
 SG_ HVB_Cell68Voltage : 31|12@0+ (0.001,2.0) [0|0] "V" Vector__XXX // Original Name: VehicleID
 SG_ HVB_Cell69Voltage : 35|12@0+ (0.001,2.0) [0|0] "V" Vector__XXX // Original Name: VehicleID
 SG_ HVB_Cell70Voltage : 55|12@0+ (0.001,2.0) [0|0] "V" Vector__XXX // Original Name: VehicleID

BO_ 1461 BMS_A24: 8 Vector__XXX // Original Name: VehicleID_CANHS_R_01
 SG_ HVB_Cell71Voltage : 7|12@0+ (0.001,2.0) [0|0] "V" Vector__XXX // Original Name: VehicleID
 SG_ HVB_Cell72Voltage : 11|12@0+ (0.001,2.0) [0|0] "V" Vector__XXX // Original Name: VehicleID
 SG_ HVB_Cell73Voltage : 31|12@0+ (0.001,2.0) [0|0] "V" Vector__XXX // Original Name: VehicleID
 SG_ HVB_Cell74Voltage : 35|12@0+ (0.001,2.0) [0|0] "V" Vector__XXX // Original Name: VehicleID
 SG_ HVB_Cell75Voltage : 55|12@0+ (0.001,2.0) [0|0] "V" Vector__XXX // Original Name: VehicleID

BO_ 1460 BMS_A25: 8 Vector__XXX // Original Name: VehicleID_CANHS_R_01
 SG_ HVB_Cell76Voltage : 7|12@0+ (0.001,2.0) [0|0] "V" Vector__XXX // Original Name: VehicleID
 SG_ HVB_Cell77Voltage : 11|12@0+ (0.001,2.0) [0|0] "V" Vector__XXX // Original Name: VehicleID
 SG_ HVB_Cell78Voltage : 31|12@0+ (0.001,2.0) [0|0] "V" Vector__XXX // Original Name: VehicleID
 SG_ HVB_Cell79Voltage : 35|12@0+ (0.001,2.0) [0|0] "V" Vector__XXX // Original Name: VehicleID
 SG_ HVB_Cell80Voltage : 55|12@0+ (0.001,2.0) [0|0] "V" Vector__XXX // Original Name: VehicleID

BO_ 1452 BMS_A26: 8 Vector__XXX // Original Name: VehicleID_CANHS_R_01
 SG_ HVB_Cell81Voltage : 7|12@0+ (0.001,2.0) [0|0] "V" Vector__XXX // Original Name: VehicleID
 SG_ HVB_Cell82Voltage : 11|12@0+ (0.001,2.0) [0|0] "V" Vector__XXX // Original Name: VehicleID
 SG_ HVB_Cell83Voltage : 31|12@0+ (0.001,2.0) [0|0] "V" Vector__XXX // Original Name: VehicleID
 SG_ HVB_Cell84Voltage : 35|12@0+ (0.001,2.0) [0|0] "V" Vector__XXX // Original Name: VehicleID
 SG_ HVB_Cell85Voltage : 55|12@0+ (0.001,2.0) [0|0] "V" Vector__XXX // Original Name: VehicleID

BO_ 1453 BMS_A27: 8 Vector__XXX // Original Name: VehicleID_CANHS_R_01
 SG_ HVB_Cell86Voltage : 7|12@0+ (0.001,2.0) [0|0] "V" Vector__XXX // Original Name: VehicleID
 SG_ HVB_Cell87Voltage : 11|12@0+ (0.001,2.0) [0|0] "V" Vector__XXX // Original Name: VehicleID
 SG_ HVB_Cell88Voltage : 31|12@0+ (0.001,2.0) [0|0] "V" Vector__XXX // Original Name: VehicleID
 SG_ HVB_Cell89Voltage : 35|12@0+ (0.001,2.0) [0|0] "V" Vector__XXX // Original Name: VehicleID
 SG_ HVB_Cell90Voltage : 55|12@0+ (0.001,2.0) [0|0] "V" Vector__XXX // Original Name: VehicleID

BO_ 1441 BMS_A28: 8 Vector__XXX // Original Name: VehicleID_CANHS_R_01
 SG_ HVB_Cell91Voltage : 7|12@0+ (0.001,2.0) [0|0] "V" Vector__XXX // Original Name: VehicleID
 SG_ HVB_Cell92Voltage : 11|12@0+ (0.001,2.0) [0|0] "V" Vector__XXX // Original Name: VehicleID
 SG_ HVB_Cell93Voltage : 31|12@0+ (0.001,2.0) [0|0] "V" Vector__XXX // Original Name: VehicleID
 SG_ HVB_Cell94Voltage : 35|12@0+ (0.001,2.0) [0|0] "V" Vector__XXX // Original Name: VehicleID
 SG_ HVB_Cell95Voltage : 55|12@0+ (0.001,2.0) [0|0] "V" Vector__XXX // Original Name: VehicleID

BO_ 1501 BMS_A29: 2 Vector__XXX // Original Name: VehicleID_CANHS_R_01
 SG_ HVB_Cell96Voltage : 7|12@0+ (0.001,2.0) [0|0] "V" Vector__XXX // Original Name: VehicleID

BO_ 1500 BMS_A30: 8 Vector__XXX // Original Name: VehicleID_CANHS_R_01
 SG_ HVB_ProbeTemp01 : 7|7@0- (1.0,-40.0) [0|0] "°C" Vector__XXX // Original Name: VehicleID
 SG_ HVB_ProbeTemp02 : 15|7@0- (1.0,-40.0) [0|0] "°C" Vector__XXX // Original Name: VehicleID
 SG_ HVB_ProbeTemp03 : 23|7@0- (1.0,-40.0) [0|0] "°C" Vector__XXX // Original Name: VehicleID
 SG_ HVB_ProbeTemp04 : 31|7@0- (1.0,-40.0) [0|0] "°C" Vector__XXX // Original Name: VehicleID
 SG_ HVB_ProbeTemp05 : 39|7@0- (1.0,-40.0) [0|0] "°C" Vector__XXX // Original Name: VehicleID
 SG_ HVB_ProbeTemp06 : 47|7@0- (1.0,-40.0) [0|0] "°C" Vector__XXX // Original Name: VehicleID
 SG_ HVB_ProbeTemp07 : 55|7@0- (1.0,-40.0) [0|0] "°C" Vector__XXX // Original Name: VehicleID
 SG_ HVB_ProbeTemp08 : 63|7@0- (1.0,-40.0) [0|0] "°C" Vector__XXX // Original Name: VehicleID

BO_ 2564485595 BMS_to_DTOOLextd: 8 Vector__XXX // Original Name: VehicleID_CANHS_R_01
 SG_ BMS_to_DTOOLextd : 7|64@0+ (1.0,0.0) [0|0] "" Vector__XXX // Original Name: VehicleID

BO_ 2564480241 DTOOL_to_BMS2extd: 8 Vector__XXX // Original Name: VehicleID_CANHS_R_01
 SG_ DTOOL_to_BMS2extd : 7|64@0+ (1.0,0.0) [0|0] "" Vector__XXX // Original Name: VehicleID

BO_ 2564479985 DTOOL_to_BMSextd: 8 Vector__XXX // Original Name: VehicleID_CANHS_R_01
 SG_ DTOOL_to_BMSextd : 7|64@0+ (1.0,0.0) [0|0] "" Vector__XXX // Original Name: VehicleID

BO_ 2615079388 FTOOLS_BMS2toCGW: 8 Vector__XXX // Original Name: VehicleID_CANHS_R_01
 SG_ FTOOLS_BMS2toCGW : 7|64@0+ (1.0,0.0) [0|0] "" Vector__XXX // Original Name: VehicleID

BO_ 2615079387 FTOOLS_BMStoCGW: 8 Vector__XXX // Original Name: VehicleID_CANHS_R_01
 SG_ FTOOLS_BMStoCGW : 7|64@0+ (1.0,0.0) [0|0] "" Vector__XXX // Original Name: VehicleID

BO_ 2615073777 FTOOLS_CGWtoBMS: 8 Vector__XXX // Original Name: VehicleID_CANHS_R_01
 SG_ FTOOLS_CGWtoBMS : 7|64@0+ (1.0,0.0) [0|0] "" Vector__XXX // Original Name: VehicleID

BO_ 2615074033 FTOOLS_CGWtoBMS2: 8 Vector__XXX // Original Name: VehicleID_CANHS_R_01
 SG_ FTOOLS_CGWtoBMS2 : 7|64@0+ (1.0,0.0) [0|0] "" Vector__XXX // Original Name: VehicleID

VAL_ 1469 AmbientLightingArea2Req 0 "Fixed value transmitted" ;
VAL_ 1469 AmbientLightingArea1Req 0 "Fixed value transmitted" ;
VAL_ 1469 AmbientLightingActivationReq 0 "Fixed value transmitted" ;
VAL_ 1469 AmbientLightingArea3Req 0 "Fixed value transmitted" ;
VAL_ 1469 MeterVolumeRequest 0 "Fixed value transmitted" ;
VAL_ 1469 AmbientLightingColorReq 0 "Fixed value transmitted" ;
VAL_ 1469 ClusterSkinRequest 0 "Fixed value transmitted" ;
VAL_ 1469 EconometerActivationRequest 0 "Fixed value transmitted" ;
VAL_ 1469 UnitDistanceDisplayRequest 0 "No request" 1 "display unit in km request" 2 "display unit in mph request" 3 "Reset request" ;
VAL_ 1469 DimmingReq 0 "Fixed value transmitted" ;
VAL_ 1469 IoniserAutoLaunchReq2 0 "Fixed value transmitted" ;
VAL_ 1469 HVchargeDisplayRequest 0 "Fixed value transmitted" ;
VAL_ 1469 MeterLanguageSyncMenu 0 "No Request" 1 "Synchronisation requested" 2 "No synchronisation requested" 3 "List menu requested" ;
VAL_ 1015 ATCVT_HiTempWarning 0 "No AT/CVT High temp warning" 1 "AT/CVT high temp warning" ;
VAL_ 1015 ATCVT_CheckWarning 0 "No AT/CVT default warning" 1 "AT/CVT default warning" ;
VAL_ 1015 ATCVT_RangeIndication 0 "OFF" 1 "P range" 2 "R range" 3 "N range" 4 "D range" 5 "S range" 6 "L range" 7 "B range" 8 "1st range" 9 "2nd range" 10 "3rd range" 11 "4th range" 12 "5th range" 13 "6th range" 14 "7th range" 15 "8th range" 16 "M1st" 17 "M2nd" 18 "M3rd" 19 "M4th" 20 "M5th" 21 "M6th" 22 "M7th" 23 "M8th" 24 "Auto 1st" 25 "Auto 2nd" 26 "Auto 3rd" 27 "Auto 4th" 28 "Auto 5th" 29 "Auto 6th" 30 "Auto 7th" 31 "Auto 8th" ;
VAL_ 1015 Full_Load 0 "Fixed value transmitted" ;
VAL_ 1015 AT_Impulsive_Selected_Mode 0 "Fixed value transmitted" ;
VAL_ 1015 AT_GearShiftRefused 0 "gear shift accepted" 1 "gear shift refused" ;
VAL_ 1015 AT_PressBrakePedalRequest 0 "No press brake pedal request" 1 "Push brake pedal requested (Shiftlock for Automatic gear or cranking with transmission range engaged for robotized gear)" ;
VAL_ 1015 AT_OpenDoorWarning 0 "Fixed value transmitted" ;
VAL_ 1015 ATSnowmodeRequest 0 "Fixed value transmitted" ;
VAL_ 1015 ATECOmodeRequest 0 "No eco mode requested" 1 "Eco mode requested" ;
VAL_ 1015 ParkLockFailureDisplay 0 "Unavailable" 1 "Parklock Failure display requested" 2 "Parklock Failure display not requested" 3 "Not used" ;
VAL_ 1015 AT_Level2FailureDisplayRequest 0 "Unavailable" 1 "No warning" 2 "AT  major failure warning (Level 2)" 3 "Protection mode activated" ;
VAL_ 1015 ClutchOverheatingIncreasing_Warning 0 "No warning" 1 "Clutch overheating increasing warning" ;
VAL_ 1015 AT_OpenDoorWarningDisplayRequest 0 "NO open door warning display" 1 "Reserved (safety)" 2 "Reserved (safety)_2" 3 "AGB open door warning display" 4 "Reserved (safety)_4" 5 "RGB open door warning display" 6 "Reserved (safety)_6" 7 "Reserved (safety)_7" ;
VAL_ 1015 GearboxInDrive 3 "Fixed value transmitted" ;
VAL_ 1015 AT_ProtectionMode_MMI 3 "Fixed value transmitted" ;
VAL_ 1502 HighBeamDisplay 0 "High beam display not requested" 1 "High beam display requested" ;
VAL_ 1502 LowBeamDisplay 0 "low beam display not requested" 1 "low beam display requested" ;
VAL_ 1502 PositionLightsDisplay 0 "position lights display not requested" 1 "position lights display requested" ;
VAL_ 1502 FrontFogLightsDisplay 0 "front fog lights display not requested" 1 "front fog lights display requested" ;
VAL_ 1502 RearFogLightStateDisplay 0 "rear fog light OFF" 1 "rear fog light ON" ;
VAL_ 1502 FlashingIndicatorStatusDisplay 0 "left and right flashing indicators OFF" 1 "left flashing indicator ON and right flashing indicator OFF" 2 "left flashing indicator OFF and right flashing indicator ON" 3 "left flashing indicator ON and right flashing indicator ON" 7 "Unavailable" ;
VAL_ 1502 KeyInfoReemissionRequest 0 "Key info display reemission not requested" 1 "Key info display reemission requested" ;
VAL_ 1502 FrontRightDoorOpenWarning 0 "No front right door open warning" 1 "front right door open warning - level 1(vehicle stopped)" 2 "front right door open warning - level 2 (vehicle running)" 3 "not used" ;
VAL_ 1502 FrontLeftDoorOpenWarning 0 "No front left door open warning" 1 "Front left door open warning - level 1(vehicle stopped)" 2 "Front left door open warning - level 2 (vehicle running)" 3 "not used" ;
VAL_ 1502 ALS_Malfunction 0 "Fixed value transmitted" ;
VAL_ 1502 PositionLightsOmissionWarning 0 "No position lights omission warning resquested" 1 "Position lights omission warning requested" 2 "not used" 3 "reserved" ;
VAL_ 1502 UnlockingSteeringColumnWarning 0 "Fixed value transmitted" ;
VAL_ 1502 SteeringLock_Failure 0 "Fixed value transmitted" ;
VAL_ 1502 BDUSafetyLineFailure 0 "Fixed value transmitted" ;
VAL_ 1502 RearRightDoorOpenWarning 0 "No rear right door open warning" 1 "rear right door open warning - level 1(vehicle stopped)" 2 "rear right door open warning - level 2 (vehicle running)" 3 "not used" ;
VAL_ 1502 RearLeftDoorOpenWarning 0 "No rear left door open warning" 1 "rear left door open warning - level 1(vehicle stopped)" 2 "rear left door open warning - level 2 (vehicle running)" 3 "not used" ;
VAL_ 1502 StartAutoInformationDisplay 0 "Fixed value transmitted" ;
VAL_ 1502 TripDisplayScrollingRequest 0 "Fixed value transmitted" ;
VAL_ 1502 ChildproofLockMalfunctionDisplay 0 "Fixed value transmitted" ;
VAL_ 1502 BadgeBatteryLow 0 "Fixed value transmitted" ;
VAL_ 1502 AutomaticLockUpActivationState 0 "Automatic lock up de-activated" 1 "Automatic lock up activated" ;
VAL_ 1502 DRLstate 0 "Fixed value transmitted" ;
VAL_ 1502 KeylessCardReaderFailureDisplay 0 "Fixed value transmitted" ;
VAL_ 1502 KeylessInfoReemissionRequest 0 "Fixed value transmitted" ;
VAL_ 1502 SmartKeylessInformationDisplay 0 "Fixed value transmitted" ;
VAL_ 1502 BrakeSwitchFaultDisplay 0 "No brake switch failure display request" 1 "Brake switch failure display requested" ;
VAL_ 1502 ClutchSwitchFaultDisplay 0 "No clutch switch failure display request" 1 "Clutch switch failure display requested" ;
VAL_ 1502 ManualLockDisplayRequest 0 "Fixed value transmitted" ;
VAL_ 1502 SingleDoorOpeningState 0 "Unavailable" 1 "Single door opening activated" 2 "Single door opening unactivated" ;
VAL_ 1502 FollowMeHomeDurationDisplay 0 "Fixed value transmitted" ;
VAL_ 1502 KeyInformationDisplay 0 "No display request" 1 "MT Cranking failed display request " 2 "AT Cranking failed display request" 3 "MT engine stall display request" 4 "AT engine stall display request" 5 "Cranking help with clutch failure display request " 6 "Cranking help with neutral failure display request" 7 "Not used" ;
VAL_ 1502 AutomaticLockUpInhibitionWarning 0 "Fixed value transmitted" ;
VAL_ 1502 VarPowSteeringFailureDisplay 0 "Fixed value transmitted" ;
VAL_ 1502 FlashingIndicatorFailureDisplay 0 "Flashing indicator failure display not requested" 1 "Flashing indicator failure display requested" ;
VAL_ 1502 StopLampFailureDisplay_BCM 0 "Stop lamp failure display not requested" 1 "Stop lamp failure display requested" ;
VAL_ 1502 MexSwitchState 0 "Fixed value transmitted" ;
VAL_ 1502 EcoModeStatusDisplay 0 "Unavailable" 1 "Eco mode status displayed" 2 "Eco mode status not displayed" 3 "Not used" ;
VAL_ 1502 GlasshatchOpenWarning 0 "Fixed value transmitted" ;
VAL_ 1502 BootOpenWarning 0 "No boot open warning" 1 "boot open warning - level 1(vehicle stopped)" 2 "boot open warning - level 2 (vehicle running)" 3 "not used" ;
VAL_ 1502 RearWiperStatus 0 "Unavailable" 1 "Rear wiper activation requested" 2 "Rear wiper de-activation requested" 3 "Not used" ;
VAL_ 1503 ADS_FailureDisplay 0 "Fixed value transmitted" ;
VAL_ 1503 WelcomePhaseState 0 "Fixed value transmitted" ;
VAL_ 1503 AHL_ActivationState 3 "Fixed value transmitted" ;
VAL_ 1503 AHL_ActivationDisplay 3 "Fixed value transmitted" ;
VAL_ 1503 AHL_FailureDisplay 3 "Fixed value transmitted" ;
VAL_ 1503 KeyReminderAlert 0 "Unavailable" 1 "No alert request" 2 "Key reminder alert display requested" 3 "Not used" ;
VAL_ 1503 LowBattVoltDisplay_BeforeSales 0 "Unavailable" 1 "NO Battery low Display Requested" 2 "Battery low Display Requested" 3 "Not used" ;
VAL_ 1503 ChildLockStateDisplay 0 "Fixed value transmitted" ;
VAL_ 1503 EcoModeActivationDisplay 0 "Fixed value transmitted" ;
VAL_ 1503 LowBatteryVoltageDisplay_BCM 0 "Fixed value transmitted" ;
VAL_ 1638 EmergencyBrakingFailure 0 "No emergency braking failure" 1 "Emergency braking failure" ;
VAL_ 1638 EBVInDefaultDisplayRequest 0 "No EBV in failure display request" 1 "EBV in failure display request" ;
VAL_ 1638 ESPDeactivatedByDriverForDisplay 0 "Fixed value transmitted" ;
VAL_ 1638 ABSInDefaultDisplayRequest 0 " No ABS in failure display requested" 1 "ABS in failure display requested" ;
VAL_ 1638 ASRActivationStateForDisplay 0 " ASR de-activated" 1 "ASR activated" ;
VAL_ 1638 ESPActivationStateForDisplay 0 "ESP desactivated " 1 "ESP activated" ;
VAL_ 1638 ESPInDefaultDisplayRequest 0 "No ESP in failure display request" 1 "ESP in failure display requested" ;
VAL_ 1638 ESPInRegulationDisplayRequest 0 "No ESP in regulation display request" 1 "ESP in regulation display requested" ;
VAL_ 1638 ABSorESPToBeCalibrated 0 "No warning : ECU operational" 1 "ECU to be calibrated warning" ;
VAL_ 1638 ABSorESPInCalibratingDiag 0 "No ABS or ESP in calibrating diagnosis session  warning : Nominal Situation or Diagnosis Reading Session" 1 "ABS or ESP in Calibrating Diagnosis  Session warning" ;
VAL_ 1638 FHSA_MalfunctionDisplayRequest 0 "Fixed value transmitted" ;
VAL_ 1638 FHSA_DriverActionRequest 0 "Fixed value transmitted" ;
VAL_ 1638 FHSA_HoldStatusDisplayRequest 0 "Fixed value transmitted" ;
VAL_ 1638 FHSA_DeactivationDisplayRequest 0 "Fixed value transmitted" ;
VAL_ 1638 ABS_ESPLampsAutoCheck 0 "Fixed value transmitted" ;
VAL_ 1638 HSAFailureDisplayRequest 0 "No HSA failure display requested" 1 "HSA failure display requested" ;
VAL_ 1638 ACCInactiveRegulationDisplay 0 "Fixed value transmitted" ;
VAL_ 1638 RST_EspAsrSportMode 0 "Fixed value transmitted" ;
VAL_ 1638 VSUStateDisplayRequest 0 "Fixed value transmitted" ;
VAL_ 1638 TPW_AckResetDriver 0 "Unvailable Value" 1 "Reset driver NOT  taken into account" 2 "Reset driver taken into account" 3 "Not Used" ;
VAL_ 1638 TPW_Status 0 "System OK" 1 "Tyre under inflated" 2 "Failure" 3 "TPW not avalaible" ;
VAL_ 1638 ExtendedGripModeDisplayRequest 0 "Fixed value transmitted" ;
VAL_ 1638 HSA_HoldStatusDisplayRequest 0 "Fixed value transmitted" ;
VAL_ 1507 LDW_SoundType 0 "Fixed value transmitted" ;
VAL_ 1507 LDW_SoundLevel 0 "Fixed value transmitted" ;
VAL_ 1507 LDW_SoundLevelState 3 "Fixed value transmitted" ;
VAL_ 1507 LDW_TimeToAlertState 2 "Fixed value transmitted" ;
VAL_ 1507 LDW_RightLeftAlert 0 "Fixed value transmitted" ;
VAL_ 1507 LDW_FailureTypeDisplay 0 "NO failure message" 1 "Failure message 1" 2 "Reserved" 3 "Reserved_3" 4 "Reserved_4" 5 "Not Used" 6 "Not Used_6" 7 "Not Used_7" ;
VAL_ 1507 LDW_MonitoringDisplay 0 "Unavailable" 1 "LDW monitored" 2 "LDW NOT monitored" 3 "LDW OFF" ;
VAL_ 1507 AHL_DefaultTypeDisplay 0 "Fixed value transmitted" ;
VAL_ 1507 LDW_Alert 0 "Reserved (safety)" 1 "No alert requested                            " 2 "Alert requested    " 3 "Reserved (safety)_3" ;
VAL_ 1640 AQMFragIntensityState 0 "Fixed value transmitted" ;
VAL_ 1640 ThermalComfortEcoAdvice 0 "Fixed value transmitted" ;
VAL_ 1640 ClimAQSActivationState 0 "Unavailable" 1 "Activated" 2 "Not activated" 3 "Not used" ;
VAL_ 1640 IoniserAutoLaunchState 0 "Fixed value transmitted" ;
VAL_ 1640 AQMIoniserModeState 0 "Fixed value transmitted" ;
VAL_ 1640 AQMFragSelectState 0 "Fixed value transmitted" ;
VAL_ 1689 ClimModeTypeDisplay 0 "No display" 1 "Auto Mode" 2 "Eco Mode" 3 "Clearness Mode" 4 "Manual Mode" 5 "OFF" 6 "Not Used" 7 "Not Used_7" ;
VAL_ 1689 ClimRearDefrostDisplay 0 "No display" 1 "Rear defrost ON" 2 "Rear defrost OFF" 3 "Not Used" ;
VAL_ 1689 ClimOFFButtonDisplay 0 "No display" 1 "Clim OFF Button activated" 2 "Clim OFF button deactivated" 3 "Not Used" ;
VAL_ 1689 ClimTempDisplay 0 "No display" 8 "Display Lo" 10 "Display Hi" ;
VAL_ 1689 ClimECOModeStatusDisplay 0 "No display" 1 "Activated" 2 "Not Activated" 3 "Unavailable" ;
VAL_ 1689 ClimForcedRecyDisplay 0 "No display" 1 "Recycling On" 2 "Recycling OFF" 3 "Not Used" ;
VAL_ 1689 ClimFlowDistrDisplay 0 "No display" 1 "Feet" 2 "Aerator " 3 "Feet + Aerator " 4 "Mild flow " 5 "Feet + Mild flow " 6 "Mild flow + Aerator" 7 "Feet + Aerator Mild flow " 8 "Defrost " 9 "Feet + Defrost " 10 "Aerator + Defrost " 11 "Feet + Aerator + Defrost " 12 "Mild flow + Defrost " 13 "Feet + Mild flow + Defrost " 14 "Aerator + Mild flow + Defrost " 15 "Feet + Aerator + Mild flow + Defrost " ;
VAL_ 1689 ClimLastFuncModifiedByCustomer 0 "No last action" 1 "Temperature" 2 "Not Used" 3 "Rear defrost" 4 "Clearness" 5 "Flow Distribution" 6 "Forced Recycling" 7 "OFF Button" 8 "Blower Level" 9 "Conso button" 10 "Auto" 11 "AC Off" 12 "Not used" 13 "Not used_13" 14 "Not used_14" 15 "Not used_15" ;
VAL_ 1689 ClimBlowerLevelDisplay 0 "No display" 1 "Level 1" 2 "Level 2" 3 "Level 3" 4 "Level 4" 5 "Level 5" 6 "Level 6" 7 "Level 7" 8 "Level 8" 9 "Level 9" 10 "Level 10" 11 "Level 11" 12 "Level 12" 13 "Level 13" 14 "Level 14" 15 "Blower Off" ;
VAL_ 1689 ClimMMIActivationRequest 0 "Unavailable" 1 "No MMI activation requested" 2 "Wake up MMI requested" 3 "Not Used" ;
VAL_ 1689 ClimAQMIoniserTimerDisplay 0 "Fixed value transmitted" ;
VAL_ 1689 ClimAQMIoniserMaxTimerDisplay 0 "Fixed value transmitted" ;
VAL_ 1689 ClimACOffDisplay 0 "No display" 1 "AC Off" 2 "AC Off Deactivated" 3 "Not used" ;
VAL_ 1689 ClimAutoDisplay 0 "No display" 1 "Auto activated" 2 "Auto not activated" 3 "Not used" ;
VAL_ 1689 ClimEcoLowSocDisplay 0 "No display request" 1 "Display Low Soc Eco clim" ;
VAL_ 1689 ClimOFFPromptingDisplay 0 "Fixed value transmitted" ;
VAL_ 1689 EnergyFlowForThermalComfortDisplay 0 "Unavailable" 1 "No display" 2 "Display" 3 "Not used" ;
VAL_ 1689 ClimDisplayMenuPC 0 "Fixed value transmitted" ;
VAL_ 1689 ClimClearnessDisplay 0 "No display" 1 "Clearness ON" 2 "Clearness OFF" 3 "Not Used" ;
VAL_ 1642 CruiseControlStatusDisplay 0 "Cruise Control (CC) and Speed Limit (SL) OFF" 1 "SL active" 2 "SL on and (awaiting or suspended)" 3 "SL requested and in failure" 4 "CC active" 5 "CC ON and ( awaiting  or suspended)" 6 "CC requested and in failure" 7 "unavailable" ;
VAL_ 1642 DieselPreHeating 0 "Fixed value transmitted" ;
VAL_ 1642 FuelConsumptionType 0 "Fixed value transmitted" ;
VAL_ 1642 ParticulateFilterFailureDisplay 0 "Fixed value transmitted" ;
VAL_ 1642 ParticulateFilterState 0 "Fixed value transmitted" ;
VAL_ 1642 DieselFilterWaterDetection 0 "Fixed value transmitted" ;
VAL_ 1642 WarningWaterTemp 0 "no water temperature warning" 1 "water temperature warning" ;
VAL_ 1642 EngineControlFailureLevel2 0 "no Engine Control Failure Level 2 create by stoping the engine" 1 "Engine Control Failure Level 2 create by stoping the engine" ;
VAL_ 1642 EngineControlFailureLevel1 0 "no Engine Control Failure Level 1" 1 "Engine Control Failure Level 1" ;
VAL_ 1642 OverspeedIndicationDisplayReq 0 "No CC/SL over speed indication display requested" 1 "CC/SL over speed indication display requested" ;
VAL_ 1642 DMSActivationRefusedDisplay 0 "Fixed value transmitted" ;
VAL_ 1642 DMSFailureDisplay 0 "Fixed value transmitted" ;
VAL_ 1642 DMSActivationStateDisplay 0 "Fixed value transmitted" ;
VAL_ 1642 RST_GearShift 0 "Fixed value transmitted" ;
VAL_ 1642 LPGFlowSwitchedOFFWarning 0 "Fixed value transmitted" ;
VAL_ 1642 CCSpeedReachedDisplayReq 0 "Fixed value transmitted" ;
VAL_ 1642 FreeShift 0 "No display request (no freeshift function or not equipped)" 1 "UpShift display resquest" 2 "DownShift display request " 3 "No Shift change display Request (by freeshift function)" ;
VAL_ 1642 AdditionalTankFuelLowLevel 0 "Fixed value transmitted" ;
VAL_ 1642 OverSpeedAlert_SL 0 "Involuntary SL over speed warning not requested" 1 "Involuntary SL over speed warning requested" ;
VAL_ 1642 RST_VehicleMode_MMI 0 "Fixed value transmitted" ;
VAL_ 1608 SCR_WarningDISDisplay 3 "Fixed value transmitted" ;
VAL_ 1608 SailingIdleDisplay 0 "Fixed value transmitted" ;
VAL_ 1608 SailingActivationIdleStatus 0 "Fixed value transmitted" ;
VAL_ 1608 SCR_WarningPostDISDisplay 3 "Fixed value transmitted" ;
VAL_ 1608 SCR_QualityWarningBeforeDISDisplay 3 "Fixed value transmitted" ;
VAL_ 1608 SCR_WarningBeforeDISDisplay 3 "Fixed value transmitted" ;
VAL_ 1608 LPGModeDisplayRequest 0 "Fixed value transmitted" ;
VAL_ 1608 SCR_DISWarningDisplayReactivation 0 "Fixed value transmitted" ;
VAL_ 1608 FlexFuelPreHeatingDisplay 0 "Fixed value transmitted" ;
VAL_ 1608 SCR_DISFinalWarningDisplay 3 "Fixed value transmitted" ;
VAL_ 1608 CapFuelTankStatusDisplay 0 "Unavailable" 1 "Cap Fuel Tank ON Display request" 2 "Cap Fuel Tank OFF Display request" 3 "Not used" ;
VAL_ 1608 LPG_NGSystemMalfunction 0 "no failure" 1 "LPG/NG system failure" ;
VAL_ 1050 StartAutoInformationDisplay_ECM 0 "No AutoStart Info Display" 1 "Start Auto Help Display" 2 "Start Auto Help Failure Display" 3 "Not used" ;
VAL_ 1050 StopStartSwitchMMI 0 "S&S Switch MMI  not requested" 1 "S&S Switch MMI requested" ;
VAL_ 1050 StopStartExitReminderDisplay_ECM 0 "Unavailable" 1 "Stop Start Reminder display requested" 2 "Stop Start Reminder display not requested" 3 "Not used" ;
VAL_ 1050 StopAutoUnavailableDisplayRequest_ECM 0 "NO Stop Auto Unavailable Display Request" 1 "Stop Auto Unavailable Display Request" ;
VAL_ 1050 StopStartStateDisplayRequest_ECM 0 "No SS State Display Request" 1 "SS Activation Display Request" 2 "SS Desactivation Display Request" 3 "StopStart Display Unavailibility for Failure" ;
VAL_ 1050 BattWarnReq_Level_Lo_ECM 0 "No Request " 1 "Request" ;
VAL_ 1050 BattWarnReq_Level_Hi_ECM 0 "No Request " 1 "Request" ;
VAL_ 1050 ECM_OilPressureSwitchFaultDisplay 0 "Fixed value transmitted" ;
VAL_ 1050 DeclutchPromptingDisplayRequest_ECM 0 "Unavailable" 1 "Prompting for declutch display request" 2 "Prompting for declutch display not requested" 3 "Not used" ;
VAL_ 1050 StopStartManualCrankingDisplay 0 "No Display Requested" 1 "Manual Start Message 1 requested" 2 "Manual Start Message 2 requested" 3 "Manual Start Message 3 requested" 4 "Manual Start Message 4 requested" 5 "Manual Start Message 5 requested" 6 "Manual Start Message 6 requested" 7 "Not Used" ;
VAL_ 1050 ManualPartFilterRegeStatus 0 "No DPF rege request" 1 "Rege needed speed condition" 2 "Rege needed" 3 "Rege ongoing" ;
VAL_ 1050 GasLowLevelAlertDisplayRequest 0 "Fuel level OK" 1 "Fuel level low" ;
VAL_ 1050 GasInstantCarburationMod 0 "Gasoline mode" 1 "LPG or CNG" ;
VAL_ 1050 StopAutoStateDisplayRequest_ECM 0 "NO Stop Auto Display Request" 1 "Stop Auto Display Request" ;
VAL_ 1050 OilPressureWarning_ECM 0 "Fixed value transmitted" ;
VAL_ 1649 VoltageMeasurementFailureDisplay 1 "Fixed value transmitted" ;
VAL_ 1649 StopLampFailureDisplay 0 "Fixed value transmitted" ;
VAL_ 1649 LowBatteryVoltageDisplay 0 "Fixed value transmitted" ;
VAL_ 1649 ALS_Malfunction 0 "Fixed value transmitted" ;
VAL_ 1649 LowBeamFailureDisplay_v2 0 "No Low Beam Failure" 1 "Low Beam Failure" 2 "Low Beam Failure re-emission" 3 "Not used" ;
VAL_ 1649 FollowMeHomeDurationDisplay_EMM 0 "No Follow me home duration Display" 1 "Follow me home duration : 30s" 2 "Follow me home duration : 60s" 3 "Follow me home duration : 90s" 4 "Follow me home duration : 120s" 5 "Not Used" 6 "Not Used_6" 7 "Not Used_7" ;
VAL_ 1649 AmbientLightingPatternState 0 "Fixed value transmitted" ;
VAL_ 1649 AmbiLightColorStatus 0 "Fixed value transmitted" ;
VAL_ 1618 Battery14VLowDisplayRequest 0 "Fixed value transmitted" ;
VAL_ 1618 ElectricalEngineState 0 "ElectricalEngine OK" 1 "ElectricalEngine not OK" ;
VAL_ 1618 CrankingRequest 0 "Fixed value transmitted" ;
VAL_ 1618 ETAlertIsolationLevel1 0 "Unavailable" 1 "No ET Alert Isolation Level 1 Requested" 2 "ET Alert Isolation Level 1 Requested" 3 "not used" ;
VAL_ 1618 ETAlertETSDefault 0 "Unavailable" 1 "No ET Alert ETS Default Requested" 2 "ET Alert ETS Default Requested" 3 "not used" ;
VAL_ 1618 ETAlertRepairETSDefault 0 "Unavailable" 1 "No ET Alert Repair ETS Default Requested" 2 "ET Alert Repair ETS Default Requested" 3 "not used" ;
VAL_ 1618 Battery14VWarningDisplayRequest 0 "Fixed value transmitted" ;
VAL_ 1618 ETAlertIsolationLevel2 0 "Unavailable" 1 "No ET Alert Isolation Level 2 Requested" 2 "ET Alert Isolation Level 2 Requested" 3 "not used" ;
VAL_ 1618 ETAlertDCDCDefault 0 "Unavailable" 1 "No ET Alert DCDC Default Requested" 2 "ET Alert DCDC Default Requested" 3 "not used" ;
VAL_ 1618 ETAlertPerfLimitation2 0 "Fixed value transmitted" ;
VAL_ 1618 ETAlertPerfLimitation1 0 "Fixed value transmitted" ;
VAL_ 1618 ETAlertMotorDefault 0 "Unavailable" 1 "No ET Alert Motor Default Requested" 2 "ET Alert Motor Default Requested" 3 "not used" ;
VAL_ 1618 SCH_StopLampRequest 0 "Reserved" 1 "Stop lamps OFF request" 2 "Stop lamps ON request" 3 "Reserved_3" ;
VAL_ 1618 SCH_WarningRequest 0 "Fixed value transmitted" ;
VAL_ 1618 ETAlertPerfLimitation3 0 "Fixed value transmitted" ;
VAL_ 1618 EMOverSpeed 0 "Not used" 1 "No EM OverSpeed" 2 "EM OverSpeed" 3 "Unvailable Value" ;
VAL_ 1620 UnballastStateDisplay 0 "Fixed value transmitted" ;
VAL_ 1620 SnowModeRequest 0 "Fixed value transmitted" ;
VAL_ 1620 PedalPressRequested 0 "Fixed value transmitted" ;
VAL_ 1620 HVBatteryUnballastAlert 0 "No HV Battery Unballast Alert" 1 "HV Battery Unballast Alert" ;
VAL_ 1620 DriverWalkAwayEngineON 0 "driver is not walking away" 1 "driver is walking away" ;
VAL_ 1620 ChargingPlugConnected 0 "Charging Plug is NOT Connected" 1 "Charging Plug is Connected" ;
VAL_ 1620 BoilerStateDisplay 0 "Fixed value transmitted" ;
VAL_ 1620 BoilerLevelStateDisplay 0 "Fixed value transmitted" ;
VAL_ 1620 HVBatteryFailureDisplay 0 "No alert" 1 "Battery minor failure alert" 2 "Battery major failure alert" 3 "not used" ;
VAL_ 1620 DriverWalkAwayBoilerON 0 "Fixed value transmitted" ;
VAL_ 1620 SelectedGear 0 "Fixed value transmitted" ;
VAL_ 1620 PreHeatingState 0 "Fixed value transmitted" ;
VAL_ 1620 ElectricalChargingType 0 "Fixed value transmitted" ;
VAL_ 1620 DriverWalkAwayOnParking_Request 0 "Fixed value transmitted" ;
VAL_ 1620 HVBatteryLow 0 "No HV Battery Low Display Requested" 1 "HV Battery Low Display Requested" ;
VAL_ 1616 EnergyFlowForTractionDisplay 0 "Unavailable" 1 "No display" 2 "Display" 3 "Not used" ;
VAL_ 1616 EnergyFlowForThermalComfortDisplay 0 "Unavailable" 1 "No display" 2 "Display" 3 "Not used" ;
VAL_ 1616 EnergyFlowForHardBrakingDisplay 0 "Fixed value transmitted" ;
VAL_ 1616 EnergyFlowForEnergyRecoveringDisplay 0 "Unavailable" 1 "No display" 2 "Display" 3 "Not used" ;
VAL_ 1616 QuickDropUnlockedDisplay 0 "Fixed value transmitted" ;
VAL_ 1616 QuickDropLockFailureDisplay 0 "Fixed value transmitted" ;
VAL_ 1616 QuickDropIterationExceededDisplay 0 "Fixed value transmitted" ;
VAL_ 1616 ShortRangeDisplay 0 "Fixed value transmitted" ;
VAL_ 1616 CrankingPluggedDisplay 0 "Unavailable" 1 "Cranking unavailable while plugged display request" 2 "No cranking unavailable while plugged display requested" 3 "Not used" ;
VAL_ 1616 EBAAlertLevel2 0 "Unavailable" 1 "No EBA Alert Level2 requested" 2 "EBA Alert Level2 requested" 3 "not used" ;
VAL_ 1616 EBAAlertLevel1 0 "Unavailable" 1 "No EBA Alert Level1 requested" 2 "EBA Alert Level1 requested" 3 "not used" ;
VAL_ 1616 JBDefaultLevel2 0 "Fixed value transmitted" ;
VAL_ 1616 JBDefaultLevel1 0 "Fixed value transmitted" ;
VAL_ 1616 GearboxChangeOnCrankingRequest 0 "No gearbox lever change requested " 1 "Gearbox P position requested" 2 "Gearbox N position requested" 3 "unavailable value" ;
VAL_ 1616 HVConnectionStatusDisplay 0 "Fixed value transmitted" ;
VAL_ 1616 PreHeatingStateDisplay 0 "No pre heating wanted" 1 "Pre heating impossible" 2 "Pre heating wanted" 3 "Pre heating in progress" 4 "Pre heating ended" 5 "Not Used" 6 "Not Used_6" 7 "Not Used_7" ;
VAL_ 1616 ClimProgrammedPCDisplay 0 "No pre-heating requested" 1 "Pre heating time 1" 2 "Pre heating time 2" 3 "Unavailable" ;
VAL_ 1616 RadarRecuperationStatusDisplay 0 "OFF" 1 "ON not active" 2 "ON active" 3 "Unavailable" ;
VAL_ 1616 EngineDryingDisplayRequest 0 "No drying alert" 1 "Drying in progress before charging" 2 "Drying in progress" 3 "Not used" ;
VAL_ 1627 EcoModeActivationDisplay 0 "Fixed value transmitted" ;
VAL_ 1627 ModeEcoIncitationPrompting 0 "Fixed value transmitted" ;
VAL_ 1627 EcoModeOverPassed 0 "Unavailable" 1 "Eco mode over passed display requested" 2 "Eco mode over passed display not requested" 3 "Not used" ;
VAL_ 1627 EcoModeFailureDisplay 0 "Fixed value transmitted" ;
VAL_ 1627 EcoModeStatusDisplay 0 "Unavailable" 1 "Eco mode status displayed" 2 "Eco mode status not displayed" 3 "Not used" ;
VAL_ 1627 ParkPositionRequestedDisplay 0 "Not used" 1 "No alert 'Set Park for Charge'" 2 "Alert 'Set Park for Charge'" 3 "Unavailable" ;
VAL_ 1627 ChargingStatusDisplay 0 "No charge" 1 "Waiting a planned charge" 2 "Ended charge" 3 "Charge in progress" 4 "Charge failure" 5 "Waiting for current charge" 6 "Energy Flap opened: welcome MMI" 7 "Unavailable" ;
VAL_ 1591 ETAlertSpotCharge 0 "No Fault Type" 1 "not used" 2 "not used_2" 3 "Connexion Problem" 4 "Spot To Check" 5 "Power Supply Cutoff" 6 "Plug Signal lost" 7 "not used_7" ;
VAL_ 1591 OpenChargeFlapWarning_Display 0 "Fixed value transmitted" ;
VAL_ 1592 Battery14vToBeChanged_Display 0 "Fixed value transmitted" ;
VAL_ 1592 StartingProhibitionDisplayRequest 0 "Not used" 1 "Starting prohibited display requested" 2 "Starting prohibited display not  requested" 3 "Unavailable" ;
VAL_ 1592 TowingProhibitionDisplayRequest 0 "Not used" 1 "Vehicle towable display requested" 2 "Vehicle not towable display requested" 3 "Unavailable" ;
VAL_ 1592 HVCrashDetectionOutOfOrderDisplay 0 "Fixed value transmitted" ;
VAL_ 1592 LowBatt14VoltDisplay_EV 0 "Fixed value transmitted" ;
VAL_ 1651 RearLeftWheelState 0 "pressure OK" 1 "No pressure information (sensor missing)" 2 "Reserved" 3 "Not used" 4 "Not used_4" 5 "Flat tyre(lower than 2nd warning threshold)" 6 "tyre under inflated (pressure lower than 1st warning threshold)" 7 "Not used_7" ;
VAL_ 1651 RearRightWheelState 0 "pressure OK" 1 "No pressure information (sensor missing)" 2 "Reserved" 3 "Not Used" 4 "Not Used_4" 5 "Flat tyre(lower than 2nd warning threshold)" 6 "tyre under inflated (pressure lower than 1st warning threshold)" 7 "Not Used_7" ;
VAL_ 1651 TPMSFailureWarningRequest 0 "Fixed value transmitted" ;
VAL_ 1651 SpeedPressureMisadaptation 0 "Fixed value transmitted" ;
VAL_ 1651 Right_LeftImbalance 0 "Fixed value transmitted" ;
VAL_ 1651 FrontLeftWheelState 0 "pressure OK" 1 "No pressure information (sensor missing)" 2 "Reserved" 3 "Not Used" 4 "Not Used_4" 5 "flat tyre  (lower than 2nd warning threshold)" 6 "tyre under inflated (pressure lower than 1st warning threshold)" 7 "Not Used_7" ;
VAL_ 1651 FrontRightWheelState 0 "pressure OK" 1 "No pressure information (sensor missing)" 2 "Reserved" 3 "Not Used" 4 "Not Used_4" 5 "flat tyre  (lower than 2nd warning threshold)" 6 "tyre under inflated (pressure lower than 1st warning threshold)" 7 "Not Used_7" ;
VAL_ 1651 TPMS_AckResetDriver 0 "Unvailable Value" 1 "Reset driver NOT  taken into account" 2 "Reset driver taken into account" 3 "Not Used" ;
VAL_ 1675 BIC_Refuse_to_Sleep 0 "reserved" 1 "BIC refuse to sleep" 2 "BIC ready to sleep" 3 "reserved_3" ;
VAL_ 1675 CDisplayAvailability 0 "Fixed value transmitted" ;
VAL_ 1675 TimeFormatDisplay 0 "12h Time Format" 1 "24h Time Format" ;
VAL_ 1675 RemoteControlScrollingRequest 0 "no driver request" 1 "upward scrolling request " 2 "downward scrolling request " 3 "Ok button scrolling request" ;
VAL_ 1675 ForgettingPhoneWarning 0 "Fixed value transmitted" ;
VAL_ 1675 UserFeedbackAvailability 1 "Fixed value transmitted" ;
VAL_ 1675 AudioAvailability 1 "Fixed value transmitted" ;
VAL_ 765 OBD_GnrlDenCond_Stat 0 "Inactive" 1 "Active" 2 "fault" 3 "not defined" ;
VAL_ 765 OBD_ColdStartERS_Actv 0 "Inactive" 1 "Active" ;
VAL_ 765 OBD_ColdStartDenCond_Stat 0 "Inactive" 1 "Active" 2 "fault" 3 "not defined" ;
VAL_ 765 OBD_GnrlDenCond_PDTC_Delete 0 "Correct" 1 "Failure" ;
VAL_ 765 AirTemp_Outsd_Sens_Flt 0 "Correct" 1 "Failure" ;
VAL_ 765 OBD_DrvCycCond_Stat 0 "Inactive" 1 "Active" 2 "fault" 3 "not defined" ;
VAL_ 765 OBD_WarmupCond_Actv 0 "Inactive" 1 "Active" ;
VAL_ 765 OBD_IgnCycCond_Stat 0 "Inactive" 1 "Active" 2 "fault" 3 "not defined" ;
VAL_ 1095 TCU_ClimPCCustomerActiv 0 "No request" 1 "Pre heating time 1" 2 "Pre heating time 2" 3 "Pre Heating OFF request" ;
VAL_ 509 ElectricalLoadSheddingRequest 0 "Fixed value transmitted" ;
VAL_ 509 ClimFanReductionRequest 0 "Fixed value transmitted" ;
VAL_ 509 PreHeatSelectedDisplayRequest 0 "Fixed value transmitted" ;
VAL_ 509 SCH_TrunkOpeningRequest 0 "Fixed value transmitted" ;
VAL_ 509 SCH_Refuse_to_Sleep 0 "reserved" 1 "SCH refuse to sleep" 2 "SCH ready to sleep" 3 "reserved_3" ;
VAL_ 509 BoilerOnDoorOpen 0 "Fixed value transmitted" ;
VAL_ 509 PreHeatingActivation 0 "Do NOT Activate PreHeating" 1 "Activate PreHeating" ;
VAL_ 509 AT_GearShiftRefused 0 "gear shift accepted" 1 "gear shift refused" ;
VAL_ 509 SCH_BlowerRequest 0 "Fixed value transmitted" ;
VAL_ 509 BMS_TiAlertDisplay 0 "No TI alert" 1 "TI alert" ;
VAL_ 1063 HVBatteryLocked 2 "Fixed value transmitted" ;
VAL_ 1063 ChargingAlert 0 "reserved" 1 "No Charging Alert" 2 "Charging Alert" 3 "unavailable" ;
VAL_ 1063 HVConnectionStatus 3 "Fixed value transmitted" ;
VAL_ 1063 PreHeatingProgress 0 "PreHeating OFF" 1 "PreHeating Requested for H1" 2 "PreHeating Requested for H2" 3 "PreHeating Not Available" 4 "PreHeating in Progress" 5 "PreHeating Finished OK" 6 "PreHeating Finished not OK" 7 "Nor used" ;
VAL_ 1063 PTCNumberThermalRequest_EVC 15 "Fixed value transmitted" ;
VAL_ 1063 ChargeAvailable 0 "Charge not available " 1 "Charge available" ;
VAL_ 1624 DomesticPlugCurrentMax_copy 0 "Fixed value transmitted" ;
VAL_ 1624 ChargeInProgress 0 "Charge Not in Progress" 1 "Charge in Progress" ;
VAL_ 1624 SpotMalfunction 1 "Fixed value transmitted" ;
VAL_ 1070 ChargingPlugs_Status 7 "Fixed value transmitted" ;
VAL_ 1070 HVBatLevel2Failure 0 "Not used" 1 "No default" 2 "Failure: level 2 default" 3 "Unavailable value" ;
VAL_ 1070 HVBatLevel1Failure 3 "Fixed value transmitted" ;
VAL_ 1070 DomesticNetworkState_copy 1 "Fixed value transmitted" ;
VAL_ 1070 TelematicsPower_ACK 0 "Fixed value transmitted" ;
VAL_ 1070 RegenBrakingLevelDisplay 0 "No regenerative braking" 1 "Regenerative braking level 1" 2 "Regenerative braking level 2" 3 "Regenerative braking level 3" 4 "Regenerative braking level 4" 5 "Regenerative braking level 5" 6 "not used" 7 "not used_7" ;
VAL_ 1070 ElectricalPowerCutFreeze_EVC 0 "Fixed value transmitted" ;
VAL_ 504 EVCReadyAsActuator 0 "Not used" 1 "EVC Available as an actuator" 2 "EVC Not available as an actuator" 3 "Not Used" ;
VAL_ 504 FCW_RegenerativeBrakingLevel 0 "No object - Level 1" 1 "Far object - Level 2" 2 "Near 1 - Level 3" 3 "Near 2 - Level 4" 4 "Close object - Level 5" 5 "Not Used" 6 "Not Used_6" 7 "unavailable value " ;
VAL_ 504 DeclutchInProgress 3 "Fixed value transmitted" ;
VAL_ 504 UBPRequestAckbyEVC 3 "Fixed value transmitted" ;
VAL_ 504 GearRangeEngagedCurrent 0 "neutral or parking or range shifting" 1 "1st range" 2 "2nd range" 3 "3rd range" 4 "Not Used" 5 "101 reversed" 6 "Not Used_6" 7 "unavailable value " ;
VAL_ 1074 HVBatCondPriorityLevel 0 "Fixed value transmitted" ;
VAL_ 1074 HVBatteryLevelAlert 0 "Fixed value transmitted" ;
VAL_ 1074 BatVEShutDownAlert 0 "Unavailable" 1 "No +BAT VE shut down alert" 2 "+BAT VE Shut down alert" 3 "Not used" ;
VAL_ 1074 PreHeatingStateDisplay 0 "No pre heating wanted" 1 "Pre heating impossible" 2 "Pre heating wanted" 3 "Pre heating in progress" 4 "Pre heating ended" 5 "Not Used" 6 "Not Used_6" 7 "Not Used_7" ;
VAL_ 1074 ClimCompDefaultStatus 0 "No failure and ON" 1 "No failure and OFF" 2 "Downgraded" 3 "Failure" 4 "To change" 5 "Not used" 6 "Not used_6" 7 "Unavailable" ;
VAL_ 1074 PTCDefaultStatus 0 "No failure and ON" 1 "No failure and OFF" 2 "Downgraded" 3 "Failure" 4 "Not used" 5 "Not used_5" 6 "Not Used" 7 "Unavailable" ;
VAL_ 1074 CoolingFanAlimentation 0 "Fixed value transmitted" ;
VAL_ 1074 HVBatConditionningMode 0 "Fixed value transmitted" ;
VAL_ 1074 EcoModeRequest 0 "Unavailable" 1 "Eco mode requested" 2 "Eco mode not requested" 3 "Not used" ;
VAL_ 1074 DeIcingAuthorisation 3 "Fixed value transmitted" ;
VAL_ 1074 LowVoltageUnballast_Request 0 "Unavailable" 1 "No unballast request" 2 "Unballast requested" 3 "Not used" ;
VAL_ 1581 PWT_PowerLimitationAlert 0 "No alert" 1 "Alert" ;
VAL_ 1581 PowerRelayState 0 "Precharge" 1 "Closed" 2 "Opened" 3 "TransitoryState" ;
VAL_ 1081 ClimProgrammedPCActivation 0 "PreHeating Not Requested" 1 "PreHeating Time n°1 Requested" 2 "PreHeating Time n°2 Requested" 3 "Unavailable" ;
VAL_ 1081 ChillerPriorityLevel 0 "Priority level 1" 1 "Priority level 2" 2 "Priority level 3" 3 "Unavailable" ;
VAL_ 1081 ChillerActivation_Request 0 "Not used" 1 "No chiller activation requested" 2 "Chiller activation requested" 3 "Unavailable" ;
VAL_ 1588 ECALL_StateDisplay_V3 0 "No message" 1 "Not used" 2 "Not used_2" 3 "Not used_3" 4 "Manual Ecall launch " 5 "Ecall auto launch " 6 "Manual Ecall failure " 7 "Ecall launch cancelled " 8 "Ecall on going " 9 "Voice communication on going - MSD not sent " 10 "Voice communication on going - MSD sent " 11 "Voice call failure " 12 "End of voice communication " 13 "Incoming call " 14 "Not used " 15 "Ecall malfunction    " ;
VAL_ 1588 EcallFunctionFailureDisplay 0 "Fixed value transmitted" ;
VAL_ 1588 TCU_Refuse_to_Sleep 0 "reserved" 1 "TCU refuse to sleep " 2 "TCU ready to sleep" 3 "reserved_3" ;
VAL_ 1588 RemotePreACActivation 0 "No Remoted Pre AC Activation" 1 "Remoted Pre AC Activation" ;
VAL_ 1588 ExternalChargingManager 0 "Fixed value transmitted" ;
VAL_ 1588 ChargeAuthorization 0 "Fixed value transmitted" ;
VAL_ 1588 ChargeProhibited 0 "Not used" 1 "Charge achievable" 2 "Charge prohibited" 3 "Unavailable" ;
VAL_ 1588 ChargingTimerStatus 0 "Fixed value transmitted" ;
VAL_ 1588 VehicleTrackingActivationState 0 "Vehicle Tracking deactivated" 1 "Vehicle Tracking activated and bad data connection" 2 "Vehicle Tracking activated and medium data connection" 3 "Vehicle Tracking activated and good data connection" 4 "Vehicle Tracking activated and no data connection" 5 "Not used" 6 "Not used_6" 7 "Unavailable" ;
VAL_ 1588 IVC_FOTAbusyFlag 0 "IVC FOTA Busy" 1 "IVC FOTA Ready" ;
VAL_ 1588 ChargingTimerStatus_MMI 0 "Fixed value transmitted" ;
VAL_ 1588 TCU_MuteRadioOrder 0 "No mute radio order" 1 "Mute radio order" ;
VAL_ 1588 AudioLanguageRequest 0 "Unavailable value" ;
VAL_ 1588 DataWipeRequest 0 "No Data Wipe request" 1 "Data Wipe request" 2 "Reserved" 3 "Reserved_3" ;
VAL_ 1339 TimeWeekDay 0 "Monday" 1 "Tuesday" 2 "Wednesday" 3 "Thursday" 4 "Friday" 5 "Saturday" 6 "Sunday" 7 "Unavailable" ;
VAL_ 525 CrankingAuthorisation_AT_Copy 0 "cranking not allowed" 1 "cranking allowed" 2 "reserved" 3 "unavailable" ;
VAL_ 525 TransmRangeEngaged_Current_Copy 0 "declutched at rest" 1 "1st range" 2 "2nd range" 3 "3rd range" 4 "4th range" 5 "5th range" 6 "6th range" 7 "7th range" 8 "8th range" 9 "reverse" 10 "neutral or parking" 11 "CVT in continuous mode" 15 "AT in limphome" ;
VAL_ 378 TransmRangeEngaged_Current 0 "declutched at rest" 1 "1st range" 2 "2nd range" 3 "3rd range" 4 "4th range" 5 "5th range" 6 "6th range" 7 "7th range" 8 "8th range" 9 "reverse" 10 "neutral or parking" 11 "CVT in continuous mode" 12 "9th range" 13 "Not used" 14 "Not used_14" 15 "AT in limphome" ;
VAL_ 378 TransmRangeEngaged_Target 0 "declutched at rest" 1 "1st range" 2 "2nd range" 3 "3rd range" 4 "4th range" 5 "5th range" 6 "6th range" 7 "7th range" 8 "8th range" 9 "reverse" 10 "neutral or parking" 11 "CVT in continuous mode" 15 "AT in limphome" ;
VAL_ 378 ManualModeState 0 "Not Manual Mode" 1 "Manual Mode" ;
VAL_ 378 AT_TorqueControlType 0 "torque limitation without transmission change" 5 "Upper torque value limitation" 6 "Lower torque value limitation" 7 "Full torque control" ;
VAL_ 378 AnticipatedCurrentShift 0 "Unavailable" 1 "Parking/Neutral" 2 "Declutched at rest" 3 "Anticipated Current Drive" ;
VAL_ 378 ATCoolingFanSpeedRequest 0 "no engine fan speed requested" 1 "low speed engine fan speed request" 2 "Mid speed engine fan speed request (Nissan fan)" 3 "high speed engine fan speed request" ;
VAL_ 378 RGB_MajorFailure 0 "Not used" 1 "No major failure" 2 "RGB/AT  major failure" 3 "Unavailable value" ;
VAL_ 378 TorqueConverterState 0 "unlocked converter" 1 "sliding converter" 2 "locked-up converter" 3 "unavailable" ;
VAL_ 382 SportivityCriteria 0 "Fixed value transmitted" ;
VAL_ 382 N_IdleStandbySignal 0 "Fixed value transmitted" ;
VAL_ 382 N_IdleLearningSignal 0 "Fixed value transmitted" ;
VAL_ 382 CrankingAuthorisation_AT 0 "cranking not allowed" 1 "cranking allowed" 2 "reserved" 3 "unavailable" ;
VAL_ 382 AnticipatedRGBPumpState 0 "Fixed value transmitted" ;
VAL_ 382 SlipControlStatus 0 "Fixed value transmitted" ;
VAL_ 382 GearLeverPosition 0 "parking" 1 "reverse" 2 "neutral" 3 "drive" 4 "4th gear" 5 "3rd gear" 6 "2nd gear" 7 "1st gear" 8 "intermediate P/R or N/R" 9 "intermediate N/D" 10 "intermediate" 11 "manual mode" 12 "6th gear" 13 "7th gear" 14 "5th gear" 15 "not available (init or lever switched failure)" ;
VAL_ 524 ImpulsionalShiftRequest 0 "No Request" 1 "Up (+) request" 2 "Down (-) request" 3 "unavailable" ;
VAL_ 524 AT_StartStopFailureFlag 0 "No start stop failure" 1 "Start stop failure" ;
VAL_ 524 AT_StartStopMode 0 "Unavailable" 1 "Normal operation" 2 "Engine stop preparation" 3 "Running down" 4 "Stopped" 5 "Cranking" 6 "Engine stopped" 7 "Stalled" ;
VAL_ 524 AT_TorqueControlType_Copy 0 "torque limitation without transmission change" 1 "Not Used" 2 "Not Used_2" 3 "Not Used_3" 4 "Not Used_4" 5 "Upper torque value limitation" 6 "Lower torque value limitation" 7 "Full torque control" ;
VAL_ 524 AT_StartStopRequest 0 "No request" 1 "Inhibit engine stop" 2 "Engine start request" 3 "Inhibit engine start" 4 "not used" 5 "not used_5" 6 "not used_6" 7 "Unavailable" ;
VAL_ 524 AT_SailingIdleForbidden 7 "Fixed value transmitted" ;
VAL_ 524 AT_AnticipatedTorqueDownRequest 0 "Fixed value transmitted" ;
VAL_ 524 AT_ProtectionModeRequest 0 "Fixed value transmitted" ;
VAL_ 524 CreepingStatus 0 "Unavailable" 1 "Creeping Active" 2 "Creeping Not active" 3 "Not used" ;
VAL_ 390 SlipControlRequest 0 "Unvailable Value" 1 "SlipControl Inhib Request" 2 "SlipControl Inhib not Requested" 3 "Not Used" ;
VAL_ 390 ECM_TorqueRequestStatus 0 "normal" 1 "Exact torque request cannot be achieved (mesure imprecision)" 2 "Transient state preventing torque request realization" 3 "torque request can not be achieved" ;
VAL_ 390 ASR_MSRAcknowledgement 0 "data received not consistent" 1 "Data received  consistent" ;
VAL_ 394 CruiseControlStatus_forTM 0 "CC and SL inactive (OFF, in standby or inactive)" 1 "pedal recovery" 2 "CC or SL active" 3 "reserved" ;
VAL_ 394 AT_TorqueAcknowledgement 0 "data received from transmission not consistent" 1 "data received  from transmission consistent" ;
VAL_ 394 KickDownActivated 0 "kick down off" 1 "kick down activated" ;
VAL_ 394 ECM_StartStopStatus 0 "not used" 1 "Stop Start not activated state" 2 "Engine running state" 3 "Anticipation stop state" 4 "Beginning stop state" 5 "End stop state" 6 "Start enable state" 7 "Relaunch engine state" 8 "Engine stalled state" 9 "Anticipation cranking State" 10 "Injection authorization state" 11 "Cranking with estimated torque state" 12 "Without driver torque state" 13 "Take off state" 14 "Relaunch failure state" 15 "Unavailable" ;
VAL_ 394 PedalError 0 "Fixed value transmitted" ;
VAL_ 393 ECM_VerlogStatus 0 "Unavailable" 1 "Vehicle unprotected by VERLOG or by RES" 2 "Vehicle protected" 3 "Not used" ;
VAL_ 393 ECM_SailingIdleRequest 0 "Fixed value transmitted" ;
VAL_ 393 LockUpRequest 0 "Fixed value transmitted" ;
VAL_ 393 FuelCutStatus 0 "Fixed value transmitted" ;
VAL_ 393 N_IdleInstruction 0 "Fixed value transmitted" ;
VAL_ 145 CreepingRequest 0 "Unavailable" 1 "Creeping enable" 2 "Creeping disable" 3 "Not used" ;
VAL_ 145 ECM_SailingAllowance 0 "Unavailable" 1 "Sailing not allowed" 2 "Sailing allowed" 3 "Not used" ;
VAL_ 1637 EasyAccessActivationRequest 0 "Fixed value transmitted" ;
VAL_ 1637 AutoMirrorFoldingActivationReq 0 "Fixed value transmitted" ;
VAL_ 1637 SingleDoorOpeningActivationReq 0 "No single door opening request" 1 "Single door opening activation requested" 2 "Single door opening de-activation requested" ;
VAL_ 1637 AutoLockUpActivationRequest 0 "No Automatic Lock Up activation/ de-activation request" 1 "Automatic Lock Up activation request" 2 "Automatic lock up de-activation request" ;
VAL_ 1637 FrontParkAssistVolumeReq 0 "Fixed value transmitted" ;
VAL_ 1637 FrontParkAssistActivationReq 0 "Fixed value transmitted" ;
VAL_ 1637 SailingIdleActivationRequest 0 "Fixed value transmitted" ;
VAL_ 1637 DRLActivationRequest 0 "Fixed value transmitted" ;
VAL_ 1637 RearParkAssistVolumeReq 0 "Fixed value transmitted" ;
VAL_ 1637 RearParkAssistActivationReq 0 "Fixed value transmitted" ;
VAL_ 1637 LDW_TimeToAlertRequest 3 "Fixed value transmitted" ;
VAL_ 1637 AutoRearWiperActivationRequest 0 "No automatic rear wiper activation de-activation request" 1 "Automatic Rear wiper activation requested" 2 "Automatic Rear wiper de-activation requested" 3 "Not Used" ;
VAL_ 1637 LanguageConfigurationRequest 0 "Fixed value transmitted" ;
VAL_ 1637 LanguageFamilyTypeRequest 0 "Fixed value transmitted" ;
VAL_ 1637 AdvisorEcoLightingActivationRequest 0 "No request" 1 "Advisor Econometer Lighting activation Requested" 2 "Advisor Econometer Lighting de-activation Requested " 3 "Not Used" ;
VAL_ 1637 AHL_ActivationRequest 0 "Fixed value transmitted" ;
VAL_ 1637 LDW_SoundLevelRequest 0 "Fixed value transmitted" ;
VAL_ 1637 ChargingTimerRequest 0 "Fixed value transmitted" ;
VAL_ 1637 FKP_ActivationRequest 0 "Fixed value transmitted" ;
VAL_ 1637 BSW_ActivationRequest 0 "Fixed value transmitted" ;
VAL_ 1637 HFP_DefaultManeuverTypeRequest 0 "Fixed value transmitted" ;
VAL_ 1637 AmbientLightingPatternRequest2 0 "Fixed value transmitted" ;
VAL_ 1637 IKeyAccessActivationRequest 0 "Fixed value transmitted" ;
VAL_ 1637 BuzzerWAC_ActivationRequest 0 "Fixed value transmitted" ;
VAL_ 1637 WAC_APRUN_ActivationRequest 0 "Fixed value transmitted" ;
VAL_ 984 BMS12V_DisconnectionDetection 0 "Connected or switch opened" 1 "Disconnected with switch closed" ;
VAL_ 984 BMS12V_RefuseToSleep 0 "reserved" 1 "BMS12V refuse to sleep " 2 "BMS12V ready to sleep" 3 "reserved_3" ;
VAL_ 984 BMS12V_StorageFailure 0 "Limit mode" 1 "Failure mode" 2 "Nominal mode" 3 "Not used" ;
VAL_ 984 BMS12V_StorageLowerLimitVolt 0 "Low voltage limit not reached" 1 "Low voltage limit reached" ;
VAL_ 984 BMS12V_SafetyAlert 0 "No alert" 1 "Low level Alert" 2 "High level Alert" 3 "Not used" ;
VAL_ 1573 BMS_FaultType_BLMS 0 "No failure" 1 "Reserved for safety" 2 "Reserved for safety_2" 3 "High Voltage battery level 1 failure" 4 "Reserved for safety_4" 5 "Safety mode 1 flag" 6 "High Voltage battery level 2 failure" 7 "Reserved for safety_7" ;
VAL_ 1573 BMS2_FaultType_BLMS 0 "No failure" 1 "Reserved for safety" 2 "Reserved for safety_2" 3 "High Voltage battery level 1 failure" 4 "Reserved for safety_4" 5 "Safety mode 1 flag" 6 "High Voltage battery level 2 failure" 7 "Reserved for safety_7" ;
VAL_ 1570 BMS_TiAlertDisplay 0 "No TI alert" 1 "TI alert" ;
